AUTOSAR XML (schema 4-0-3)
standard types defined: Boolean, UInt16
package /AUTOSAR_Platform/DataConstrs
  range DC_Boolean: raw 0..1
  range DC_UInt16: raw 0..65535
package /PATAC/Facility/DataTypes/Implementation
  compu method COMPU_Boolean: 0=FALSE, 1=TRUE
  unit NoUnit: factor-si-to-unit=1, offset-si-to-unit=0
package /PATAC/MSM/ComponentTypes
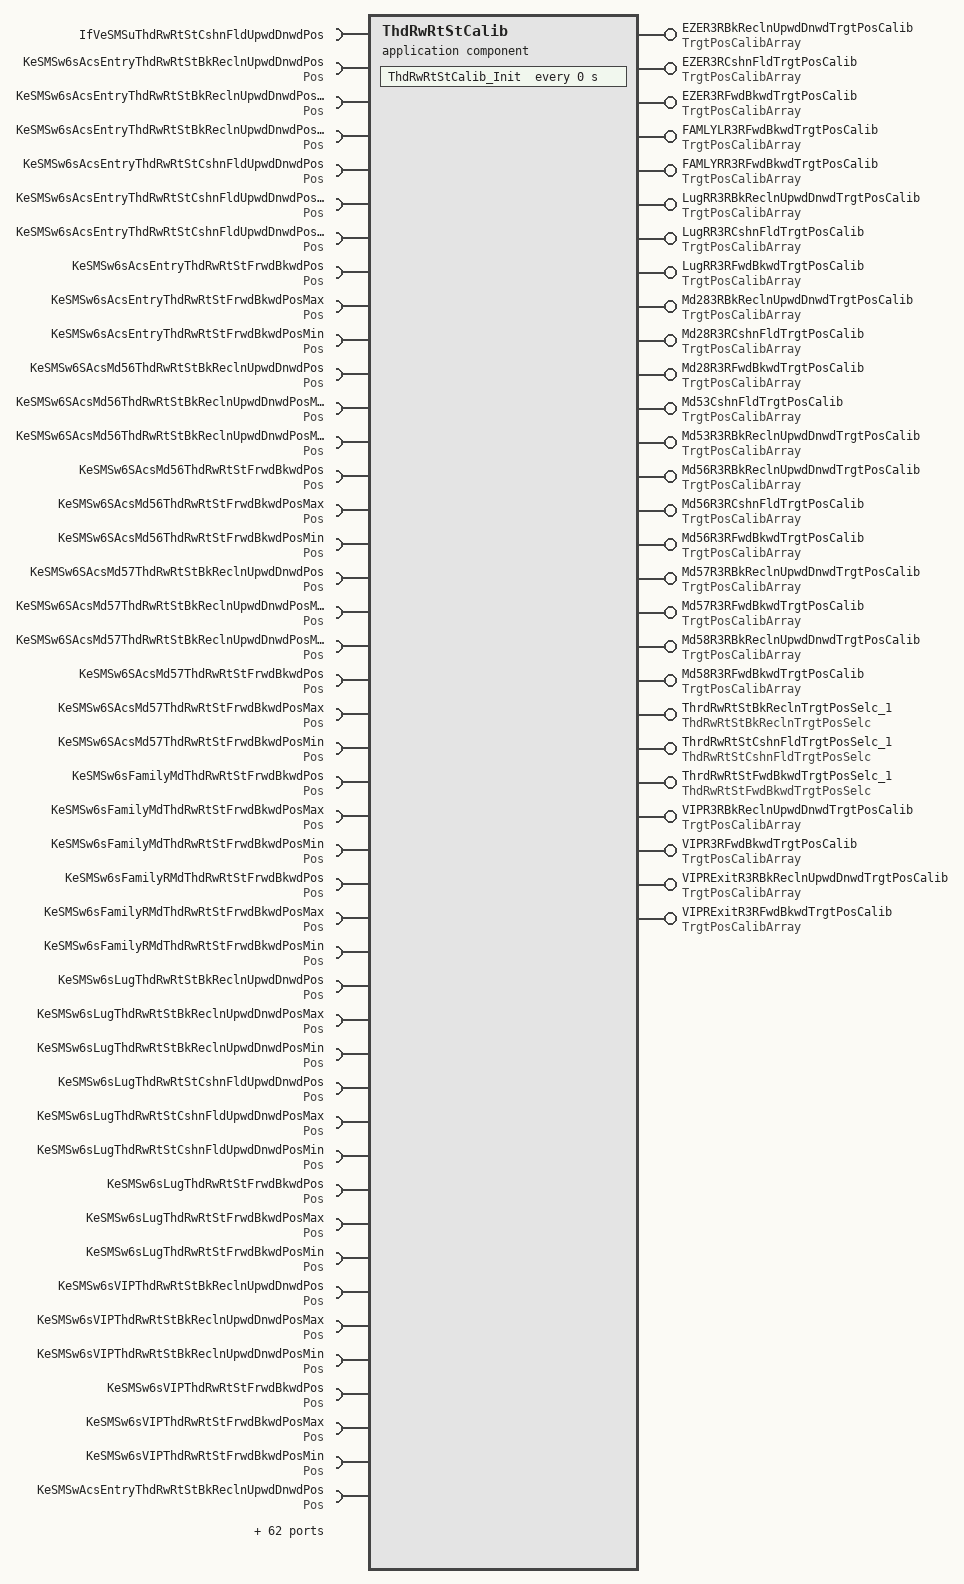
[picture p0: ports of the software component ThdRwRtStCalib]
  application sw component type ThdRwRtStCalib
    27 x provide port:
      EZER3RBkReclnUpwdDnwdTrgtPosCalib: nonqueued-sender-com-spec{data-element=TrgtPosArray, init-value=[4095, 4095, 4095]}, provided-interface=TrgtPosCalibArray
      EZER3RCshnFldTrgtPosCalib: nonqueued-sender-com-spec{data-element=TrgtPosArray, init-value=[4095, 4095, 4095]}, provided-interface=TrgtPosCalibArray
      EZER3RFwdBkwdTrgtPosCalib: nonqueued-sender-com-spec{data-element=TrgtPosArray, init-value=[4095, 4095, 4095]}, provided-interface=TrgtPosCalibArray
      FAMLYLR3RFwdBkwdTrgtPosCalib: nonqueued-sender-com-spec{data-element=TrgtPosArray, init-value=[4095, 4095, 4095]}, provided-interface=TrgtPosCalibArray
      FAMLYRR3RFwdBkwdTrgtPosCalib: nonqueued-sender-com-spec{data-element=TrgtPosArray, init-value=[4095, 4095, 4095]}, provided-interface=TrgtPosCalibArray
      LugRR3RBkReclnUpwdDnwdTrgtPosCalib: nonqueued-sender-com-spec{data-element=TrgtPosArray, init-value=[4095, 4095, 4095]}, provided-interface=TrgtPosCalibArray
      LugRR3RCshnFldTrgtPosCalib: nonqueued-sender-com-spec{data-element=TrgtPosArray, init-value=[4095, 4095, 4095]}, provided-interface=TrgtPosCalibArray
      LugRR3RFwdBkwdTrgtPosCalib: nonqueued-sender-com-spec{data-element=TrgtPosArray, init-value=[4095, 4095, 4095]}, provided-interface=TrgtPosCalibArray
      Md283RBkReclnUpwdDnwdTrgtPosCalib: nonqueued-sender-com-spec{data-element=TrgtPosArray, init-value=[4095, 4095, 4095]}, provided-interface=TrgtPosCalibArray
      Md28R3RCshnFldTrgtPosCalib: nonqueued-sender-com-spec{data-element=TrgtPosArray, init-value=[4095, 4095, 4095]}, provided-interface=TrgtPosCalibArray
      Md28R3RFwdBkwdTrgtPosCalib: nonqueued-sender-com-spec{data-element=TrgtPosArray, init-value=[4095, 4095, 4095]}, provided-interface=TrgtPosCalibArray
      Md53CshnFldTrgtPosCalib: nonqueued-sender-com-spec{data-element=TrgtPosArray, init-value=[4095, 4095, 4095]}, provided-interface=TrgtPosCalibArray
      Md53R3RBkReclnUpwdDnwdTrgtPosCalib: nonqueued-sender-com-spec{data-element=TrgtPosArray, init-value=[4095, 4095, 4095]}, provided-interface=TrgtPosCalibArray
      Md56R3RBkReclnUpwdDnwdTrgtPosCalib: nonqueued-sender-com-spec{data-element=TrgtPosArray, init-value=[4095, 4095, 4095]}, provided-interface=TrgtPosCalibArray
      Md56R3RCshnFldTrgtPosCalib: nonqueued-sender-com-spec{data-element=TrgtPosArray, init-value=[4095, 4095, 4095]}, provided-interface=TrgtPosCalibArray
      Md56R3RFwdBkwdTrgtPosCalib: nonqueued-sender-com-spec{data-element=TrgtPosArray, init-value=[4095, 4095, 4095]}, provided-interface=TrgtPosCalibArray
      Md57R3RBkReclnUpwdDnwdTrgtPosCalib: nonqueued-sender-com-spec{data-element=TrgtPosArray, init-value=[4095, 4095, 4095]}, provided-interface=TrgtPosCalibArray
      Md57R3RFwdBkwdTrgtPosCalib: nonqueued-sender-com-spec{data-element=TrgtPosArray, init-value=[4095, 4095, 4095]}, provided-interface=TrgtPosCalibArray
      Md58R3RBkReclnUpwdDnwdTrgtPosCalib: nonqueued-sender-com-spec{data-element=TrgtPosArray, init-value=[4095, 4095, 4095]}, provided-interface=TrgtPosCalibArray
      Md58R3RFwdBkwdTrgtPosCalib: nonqueued-sender-com-spec{data-element=TrgtPosArray, init-value=[4095, 4095, 4095]}, provided-interface=TrgtPosCalibArray
      ThrdRwRtStBkReclnTrgtPosSelc_1: server-com-spec{operation=ThdRwRtStBkReclnTrgtPosSelc/Cal, queue-length=1}, provided-interface=ThdRwRtStBkReclnTrgtPosSelc
      ThrdRwRtStCshnFldTrgtPosSelc_1: server-com-spec{operation=ThdRwRtStCshnFldTrgtPosSelc/Cal, queue-length=1}, provided-interface=ThdRwRtStCshnFldTrgtPosSelc
      ThrdRwRtStFwdBkwdTrgtPosSelc_1: server-com-spec{operation=ThdRwRtStFwdBkwdTrgtPosSelc/Cal, queue-length=1}, provided-interface=ThdRwRtStFwdBkwdTrgtPosSelc
      VIPR3RBkReclnUpwdDnwdTrgtPosCalib: nonqueued-sender-com-spec{data-element=TrgtPosArray, init-value=[4095, 4095, 4095]}, provided-interface=TrgtPosCalibArray
      VIPR3RFwdBkwdTrgtPosCalib: nonqueued-sender-com-spec{data-element=TrgtPosArray, init-value=[4095, 4095, 4095]}, provided-interface=TrgtPosCalibArray
      VIPRExitR3RBkReclnUpwdDnwdTrgtPosCalib: nonqueued-sender-com-spec{data-element=TrgtPosArray, init-value=[4095, 4095, 4095]}, provided-interface=TrgtPosCalibArray
      VIPRExitR3RFwdBkwdTrgtPosCalib: nonqueued-sender-com-spec{data-element=TrgtPosArray, init-value=[4095, 4095, 4095]}, provided-interface=TrgtPosCalibArray
    106 x require port:
      IfVeSMSuThdRwRtStCshnFldUpwdDnwdPos: nonqueued-receiver-com-spec{data-element=Val, filter=data-filter-type=ALWAYS, init-value=0}, required-interface=IfVeSMSuThdRwRtStCshnFldUpwdDnwdPos
      KeSMSw6sAcsEntryThdRwRtStBkReclnUpwdDnwdPos: parameter-require-com-spec{init-value=2080, parameter=Val}, required-interface=Pos
      KeSMSw6sAcsEntryThdRwRtStBkReclnUpwdDnwdPosMax: parameter-require-com-spec{init-value=2095, parameter=Val}, required-interface=Pos
      KeSMSw6sAcsEntryThdRwRtStBkReclnUpwdDnwdPosMin: parameter-require-com-spec{init-value=2080, parameter=Val}, required-interface=Pos
      KeSMSw6sAcsEntryThdRwRtStCshnFldUpwdDnwdPos: parameter-require-com-spec{init-value=0, parameter=Val}, required-interface=Pos
      KeSMSw6sAcsEntryThdRwRtStCshnFldUpwdDnwdPosMax: parameter-require-com-spec{init-value=0, parameter=Val}, required-interface=Pos
      KeSMSw6sAcsEntryThdRwRtStCshnFldUpwdDnwdPosMin: parameter-require-com-spec{init-value=0, parameter=Val}, required-interface=Pos
      KeSMSw6sAcsEntryThdRwRtStFrwdBkwdPos: parameter-require-com-spec{init-value=2760, parameter=Val}, required-interface=Pos
      KeSMSw6sAcsEntryThdRwRtStFrwdBkwdPosMax: parameter-require-com-spec{init-value=4000, parameter=Val}, required-interface=Pos
      KeSMSw6sAcsEntryThdRwRtStFrwdBkwdPosMin: parameter-require-com-spec{init-value=2760, parameter=Val}, required-interface=Pos
      KeSMSw6SAcsMd56ThdRwRtStBkReclnUpwdDnwdPos: parameter-require-com-spec{init-value=2080, parameter=Val}, required-interface=Pos
      KeSMSw6SAcsMd56ThdRwRtStBkReclnUpwdDnwdPosMax: parameter-require-com-spec{init-value=2080, parameter=Val}, required-interface=Pos
      KeSMSw6SAcsMd56ThdRwRtStBkReclnUpwdDnwdPosMin: parameter-require-com-spec{init-value=2080, parameter=Val}, required-interface=Pos
      KeSMSw6SAcsMd56ThdRwRtStFrwdBkwdPos: parameter-require-com-spec{init-value=2080, parameter=Val}, required-interface=Pos
      KeSMSw6SAcsMd56ThdRwRtStFrwdBkwdPosMax: parameter-require-com-spec{init-value=2080, parameter=Val}, required-interface=Pos
      KeSMSw6SAcsMd56ThdRwRtStFrwdBkwdPosMin: parameter-require-com-spec{init-value=2080, parameter=Val}, required-interface=Pos
      KeSMSw6SAcsMd57ThdRwRtStBkReclnUpwdDnwdPos: parameter-require-com-spec{init-value=2080, parameter=Val}, required-interface=Pos
      KeSMSw6SAcsMd57ThdRwRtStBkReclnUpwdDnwdPosMax: parameter-require-com-spec{init-value=2080, parameter=Val}, required-interface=Pos
      KeSMSw6SAcsMd57ThdRwRtStBkReclnUpwdDnwdPosMin: parameter-require-com-spec{init-value=2080, parameter=Val}, required-interface=Pos
      KeSMSw6SAcsMd57ThdRwRtStFrwdBkwdPos: parameter-require-com-spec{init-value=2080, parameter=Val}, required-interface=Pos
      KeSMSw6SAcsMd57ThdRwRtStFrwdBkwdPosMax: parameter-require-com-spec{init-value=2080, parameter=Val}, required-interface=Pos
      KeSMSw6SAcsMd57ThdRwRtStFrwdBkwdPosMin: parameter-require-com-spec{init-value=2080, parameter=Val}, required-interface=Pos
      KeSMSw6sFamilyMdThdRwRtStFrwdBkwdPos: parameter-require-com-spec{init-value=0, parameter=Val}, required-interface=Pos
      KeSMSw6sFamilyMdThdRwRtStFrwdBkwdPosMax: parameter-require-com-spec{init-value=0, parameter=Val}, required-interface=Pos
      KeSMSw6sFamilyMdThdRwRtStFrwdBkwdPosMin: parameter-require-com-spec{init-value=0, parameter=Val}, required-interface=Pos
      KeSMSw6sFamilyRMdThdRwRtStFrwdBkwdPos: parameter-require-com-spec{init-value=0, parameter=Val}, required-interface=Pos
      KeSMSw6sFamilyRMdThdRwRtStFrwdBkwdPosMax: parameter-require-com-spec{init-value=0, parameter=Val}, required-interface=Pos
      KeSMSw6sFamilyRMdThdRwRtStFrwdBkwdPosMin: parameter-require-com-spec{init-value=0, parameter=Val}, required-interface=Pos
      KeSMSw6sLugThdRwRtStBkReclnUpwdDnwdPos: parameter-require-com-spec{init-value=0, parameter=Val}, required-interface=Pos
      KeSMSw6sLugThdRwRtStBkReclnUpwdDnwdPosMax: parameter-require-com-spec{init-value=0, parameter=Val}, required-interface=Pos
      KeSMSw6sLugThdRwRtStBkReclnUpwdDnwdPosMin: parameter-require-com-spec{init-value=0, parameter=Val}, required-interface=Pos
      KeSMSw6sLugThdRwRtStCshnFldUpwdDnwdPos: parameter-require-com-spec{init-value=4000, parameter=Val}, required-interface=Pos
      KeSMSw6sLugThdRwRtStCshnFldUpwdDnwdPosMax: parameter-require-com-spec{init-value=4000, parameter=Val}, required-interface=Pos
      KeSMSw6sLugThdRwRtStCshnFldUpwdDnwdPosMin: parameter-require-com-spec{init-value=4000, parameter=Val}, required-interface=Pos
      KeSMSw6sLugThdRwRtStFrwdBkwdPos: parameter-require-com-spec{init-value=0, parameter=Val}, required-interface=Pos
      KeSMSw6sLugThdRwRtStFrwdBkwdPosMax: parameter-require-com-spec{init-value=0, parameter=Val}, required-interface=Pos
      KeSMSw6sLugThdRwRtStFrwdBkwdPosMin: parameter-require-com-spec{init-value=0, parameter=Val}, required-interface=Pos
      KeSMSw6sVIPThdRwRtStBkReclnUpwdDnwdPos: parameter-require-com-spec{init-value=0, parameter=Val}, required-interface=Pos
      KeSMSw6sVIPThdRwRtStBkReclnUpwdDnwdPosMax: parameter-require-com-spec{init-value=0, parameter=Val}, required-interface=Pos
      KeSMSw6sVIPThdRwRtStBkReclnUpwdDnwdPosMin: parameter-require-com-spec{init-value=0, parameter=Val}, required-interface=Pos
      KeSMSw6sVIPThdRwRtStFrwdBkwdPos: parameter-require-com-spec{init-value=4000, parameter=Val}, required-interface=Pos
      KeSMSw6sVIPThdRwRtStFrwdBkwdPosMax: parameter-require-com-spec{init-value=4000, parameter=Val}, required-interface=Pos
      KeSMSw6sVIPThdRwRtStFrwdBkwdPosMin: parameter-require-com-spec{init-value=4000, parameter=Val}, required-interface=Pos
      KeSMSwAcsEntryThdRwRtStBkReclnUpwdDnwdPos: parameter-require-com-spec{init-value=2080, parameter=Val}, required-interface=Pos
      KeSMSwAcsEntryThdRwRtStBkReclnUpwdDnwdPosMax: parameter-require-com-spec{init-value=2095, parameter=Val}, required-interface=Pos
      KeSMSwAcsEntryThdRwRtStBkReclnUpwdDnwdPosMin: parameter-require-com-spec{init-value=2080, parameter=Val}, required-interface=Pos
      KeSMSwAcsEntryThdRwRtStCshnFldUpwdDnwdPos: parameter-require-com-spec{init-value=0, parameter=Val}, required-interface=Pos
      KeSMSwAcsEntryThdRwRtStCshnFldUpwdDnwdPosMax: parameter-require-com-spec{init-value=0, parameter=Val}, required-interface=Pos
      KeSMSwAcsEntryThdRwRtStCshnFldUpwdDnwdPosMin: parameter-require-com-spec{init-value=0, parameter=Val}, required-interface=Pos
      KeSMSwAcsEntryThdRwRtStFrwdBkwdPos: parameter-require-com-spec{init-value=2760, parameter=Val}, required-interface=Pos
      KeSMSwAcsEntryThdRwRtStFrwdBkwdPosMax: parameter-require-com-spec{init-value=4000, parameter=Val}, required-interface=Pos
      KeSMSwAcsEntryThdRwRtStFrwdBkwdPosMin: parameter-require-com-spec{init-value=2760, parameter=Val}, required-interface=Pos
      KeSMSwAcsMd53ThdRwRtBkReclnUpwdDnwdPos: parameter-require-com-spec{init-value=2080, parameter=Val}, required-interface=Pos
      KeSMSwAcsMd53ThdRwRtBkReclnUpwdDnwdPosMax: parameter-require-com-spec{init-value=2080, parameter=Val}, required-interface=Pos
      KeSMSwAcsMd53ThdRwRtBkReclnUpwdDnwdPosMin: parameter-require-com-spec{init-value=2080, parameter=Val}, required-interface=Pos
      KeSMSwAcsMd53ThdRwRtFldUpwdDnwdPos: parameter-require-com-spec{init-value=0, parameter=Val}, required-interface=Pos
      KeSMSwAcsMd53ThdRwRtFldUpwdDnwdPosMax: parameter-require-com-spec{init-value=0, parameter=Val}, required-interface=Pos
      KeSMSwAcsMd53ThdRwRtFldUpwdDnwdPosMin: parameter-require-com-spec{init-value=0, parameter=Val}, required-interface=Pos
      KeSMSwAcsMd56ThdRwRtStBkReclnUpwdDnwdPos: parameter-require-com-spec{init-value=2080, parameter=Val}, required-interface=Pos
      KeSMSwAcsMd56ThdRwRtStBkReclnUpwdDnwdPosMax: parameter-require-com-spec{init-value=2080, parameter=Val}, required-interface=Pos
      KeSMSwAcsMd56ThdRwRtStBkReclnUpwdDnwdPosMin: parameter-require-com-spec{init-value=2080, parameter=Val}, required-interface=Pos
      KeSMSwAcsMd56ThdRwRtStCshnFldUpwdDnwdPos: parameter-require-com-spec{init-value=2080, parameter=Val}, required-interface=Pos
      KeSMSwAcsMd56ThdRwRtStCshnFldUpwdDnwdPosMax: parameter-require-com-spec{init-value=2080, parameter=Val}, required-interface=Pos
      KeSMSwAcsMd56ThdRwRtStCshnFldUpwdDnwdPosMin: parameter-require-com-spec{init-value=2080, parameter=Val}, required-interface=Pos
      KeSMSwAcsMd56ThdRwRtStFrwdBkwdPos: parameter-require-com-spec{init-value=2080, parameter=Val}, required-interface=Pos
      KeSMSwAcsMd56ThdRwRtStFrwdBkwdPosMax: parameter-require-com-spec{init-value=2080, parameter=Val}, required-interface=Pos
      KeSMSwAcsMd56ThdRwRtStFrwdBkwdPosMin: parameter-require-com-spec{init-value=2080, parameter=Val}, required-interface=Pos
      KeSMSwAcsMd57ThdRwRtStBkReclnUpwdDnwdPos: parameter-require-com-spec{init-value=2080, parameter=Val}, required-interface=Pos
      KeSMSwAcsMd57ThdRwRtStBkReclnUpwdDnwdPosMax: parameter-require-com-spec{init-value=2080, parameter=Val}, required-interface=Pos
      KeSMSwAcsMd57ThdRwRtStBkReclnUpwdDnwdPosMin: parameter-require-com-spec{init-value=2080, parameter=Val}, required-interface=Pos
      KeSMSwAcsMd57ThdRwRtStFrwdBkwdPos: parameter-require-com-spec{init-value=2080, parameter=Val}, required-interface=Pos
      KeSMSwAcsMd57ThdRwRtStFrwdBkwdPosMax: parameter-require-com-spec{init-value=2080, parameter=Val}, required-interface=Pos
      KeSMSwAcsMd57ThdRwRtStFrwdBkwdPosMin: parameter-require-com-spec{init-value=2080, parameter=Val}, required-interface=Pos
      KeSMSwAcsMd7ThdRwRtStBkReclnUpwdDnwdPos: parameter-require-com-spec{init-value=0, parameter=Val}, required-interface=Pos
      KeSMSwAcsMd7ThdRwRtStBkReclnUpwdDnwdPosMax: parameter-require-com-spec{init-value=0, parameter=Val}, required-interface=Pos
      KeSMSwAcsMd7ThdRwRtStBkReclnUpwdDnwdPosMin: parameter-require-com-spec{init-value=0, parameter=Val}, required-interface=Pos
      KeSMSwAcsMd7ThdRwRtStCshnFldUpwdDnwdPos: parameter-require-com-spec{init-value=0, parameter=Val}, required-interface=Pos
      KeSMSwAcsMd7ThdRwRtStCshnFldUpwdDnwdPosMax: parameter-require-com-spec{init-value=0, parameter=Val}, required-interface=Pos
      KeSMSwAcsMd7ThdRwRtStCshnFldUpwdDnwdPosMin: parameter-require-com-spec{init-value=0, parameter=Val}, required-interface=Pos
      KeSMSwAcsMd7ThdRwRtStFrwdBkwdPos: parameter-require-com-spec{init-value=0, parameter=Val}, required-interface=Pos
      KeSMSwAcsMd7ThdRwRtStFrwdBkwdPosMax: parameter-require-com-spec{init-value=0, parameter=Val}, required-interface=Pos
      KeSMSwAcsMd7ThdRwRtStFrwdBkwdPosMin: parameter-require-com-spec{init-value=0, parameter=Val}, required-interface=Pos
      KeSMSwFamilyMdThdRwRtStFrwdBkwdPos: parameter-require-com-spec{init-value=0, parameter=Val}, required-interface=Pos
      KeSMSwFamilyMdThdRwRtStFrwdBkwdPosMax: parameter-require-com-spec{init-value=0, parameter=Val}, required-interface=Pos
      KeSMSwFamilyMdThdRwRtStFrwdBkwdPosMin: parameter-require-com-spec{init-value=0, parameter=Val}, required-interface=Pos
      KeSMSwFamilyRMdThdRwRtStFrwdBkwdPos: parameter-require-com-spec{init-value=0, parameter=Val}, required-interface=Pos
      KeSMSwFamilyRMdThdRwRtStFrwdBkwdPosMax: parameter-require-com-spec{init-value=0, parameter=Val}, required-interface=Pos
      KeSMSwFamilyRMdThdRwRtStFrwdBkwdPosMin: parameter-require-com-spec{init-value=0, parameter=Val}, required-interface=Pos
      KeSMSwLugThdRwRtStBkReclnUpwdDnwdPos: parameter-require-com-spec{init-value=0, parameter=Val}, required-interface=Pos
      KeSMSwLugThdRwRtStBkReclnUpwdDnwdPosMax: parameter-require-com-spec{init-value=0, parameter=Val}, required-interface=Pos
      KeSMSwLugThdRwRtStBkReclnUpwdDnwdPosMin: parameter-require-com-spec{init-value=0, parameter=Val}, required-interface=Pos
      KeSMSwLugThdRwRtStCshnFldUpwdDnwdPos: parameter-require-com-spec{init-value=4000, parameter=Val}, required-interface=Pos
      KeSMSwLugThdRwRtStCshnFldUpwdDnwdPosMax: parameter-require-com-spec{init-value=4000, parameter=Val}, required-interface=Pos
      KeSMSwLugThdRwRtStCshnFldUpwdDnwdPosMin: parameter-require-com-spec{init-value=4000, parameter=Val}, required-interface=Pos
      KeSMSwLugThdRwRtStFrwdBkwdPos: parameter-require-com-spec{init-value=4000, parameter=Val}, required-interface=Pos
      KeSMSwLugThdRwRtStFrwdBkwdPosMax: parameter-require-com-spec{init-value=4000, parameter=Val}, required-interface=Pos
      KeSMSwLugThdRwRtStFrwdBkwdPosMin: parameter-require-com-spec{init-value=4000, parameter=Val}, required-interface=Pos
      KeSMSwVIPThdRwRtStBkReclnUpwdDnwdPos: parameter-require-com-spec{init-value=0, parameter=Val}, required-interface=Pos
      KeSMSwVIPThdRwRtStBkReclnUpwdDnwdPosMax: parameter-require-com-spec{init-value=0, parameter=Val}, required-interface=Pos
      KeSMSwVIPThdRwRtStBkReclnUpwdDnwdPosMin: parameter-require-com-spec{init-value=0, parameter=Val}, required-interface=Pos
      KeSMSwVIPThdRwRtStFrwdBkwdPos: parameter-require-com-spec{init-value=4000, parameter=Val}, required-interface=Pos
      KeSMSwVIPThdRwRtStFrwdBkwdPosMax: parameter-require-com-spec{init-value=4000, parameter=Val}, required-interface=Pos
      KeSMSwVIPThdRwRtStFrwdBkwdPosMin: parameter-require-com-spec{init-value=4000, parameter=Val}, required-interface=Pos
      Md58TrgtPos: required-com-specs=[Md58TrgtPos/Get, Md58TrgtPos/Set], required-interface=Md58TrgtPos
      StNumFlg: required-interface=StNumFlg
        required-com-specs:
          data-element=Is4s, filter=data-filter-type=ALWAYS, init-value=0
          data-element=Is6s, filter=data-filter-type=ALWAYS, init-value=0
          data-element=Is6s7s, filter=data-filter-type=ALWAYS, init-value=0
          data-element=Is7s, filter=data-filter-type=ALWAYS, init-value=0
      VIPRExit557TrgtPos: required-com-specs=[VIPRExit557TrgtPos/Get, VIPRExit557TrgtPos/Set], required-interface=VIPRExit557TrgtPos
    behavior ThdRwRtStCalib_InternalBehavior
      timing event ThdRwRtStCalib_InitEvent: start-on-event=ThdRwRtStCalib_Init, period=0
      operation invoked event OIT_ThrdRwRtStBkReclnTrgtPosSelc_1_Cal_ThrdRwRtStBkReclnTrgtPosSelc_1_Cal: start-on-event=ThrdRwRtStBkReclnTrgtPosSelc_1_Cal, operation=ThrdRwRtStBkReclnTrgtPosSelc_1.Cal
      operation invoked event OIT_ThrdRwRtStCshnFldTrgtPosSelc_1_Cal_ThrdRwRtStCshnFldTrgtPosSelc_1_Cal: start-on-event=ThrdRwRtStCshnFldTrgtPosSelc_1_Cal, operation=ThrdRwRtStCshnFldTrgtPosSelc_1.Cal
      operation invoked event OIT_ThrdRwRtStFwdBkwdTrgtPosSelc_1_Cal_ThrdRwRtStFwdBkwdTrgtPosSelc_1_Cal: start-on-event=ThrdRwRtStFwdBkwdTrgtPosSelc_1_Cal, operation=ThrdRwRtStFwdBkwdTrgtPosSelc_1.Cal
      4 x runnable:
        ThdRwRtStCalib_Init
          102 x parameter access:
            PA_KeSMSw6sAcsEntryThdRwRtStBkReclnUpwdDnwdPos_Val: accessed-parameter=KeSMSw6sAcsEntryThdRwRtStBkReclnUpwdDnwdPos.Val
            PA_KeSMSw6sAcsEntryThdRwRtStBkReclnUpwdDnwdPosMax_Val: accessed-parameter=KeSMSw6sAcsEntryThdRwRtStBkReclnUpwdDnwdPosMax.Val
            PA_KeSMSw6sAcsEntryThdRwRtStBkReclnUpwdDnwdPosMin_Val: accessed-parameter=KeSMSw6sAcsEntryThdRwRtStBkReclnUpwdDnwdPosMin.Val
            PA_KeSMSw6sAcsEntryThdRwRtStCshnFldUpwdDnwdPos_Val: accessed-parameter=KeSMSw6sAcsEntryThdRwRtStCshnFldUpwdDnwdPos.Val
            PA_KeSMSw6sAcsEntryThdRwRtStCshnFldUpwdDnwdPosMax_Val: accessed-parameter=KeSMSw6sAcsEntryThdRwRtStCshnFldUpwdDnwdPosMax.Val
            PA_KeSMSw6sAcsEntryThdRwRtStCshnFldUpwdDnwdPosMin_Val: accessed-parameter=KeSMSw6sAcsEntryThdRwRtStCshnFldUpwdDnwdPosMin.Val
            PA_KeSMSw6sAcsEntryThdRwRtStFrwdBkwdPos_Val: accessed-parameter=KeSMSw6sAcsEntryThdRwRtStFrwdBkwdPos.Val
            PA_KeSMSw6sAcsEntryThdRwRtStFrwdBkwdPosMax_Val: accessed-parameter=KeSMSw6sAcsEntryThdRwRtStFrwdBkwdPosMax.Val
            PA_KeSMSw6sAcsEntryThdRwRtStFrwdBkwdPosMin_Val: accessed-parameter=KeSMSw6sAcsEntryThdRwRtStFrwdBkwdPosMin.Val
            PA_KeSMSw6SAcsMd56ThdRwRtStBkReclnUpwdDnwdPos_Val: accessed-parameter=KeSMSw6SAcsMd56ThdRwRtStBkReclnUpwdDnwdPos.Val
            PA_KeSMSw6SAcsMd56ThdRwRtStBkReclnUpwdDnwdPosMax_Val: accessed-parameter=KeSMSw6SAcsMd56ThdRwRtStBkReclnUpwdDnwdPosMax.Val
            PA_KeSMSw6SAcsMd56ThdRwRtStBkReclnUpwdDnwdPosMin_Val: accessed-parameter=KeSMSw6SAcsMd56ThdRwRtStBkReclnUpwdDnwdPosMin.Val
            PA_KeSMSw6SAcsMd56ThdRwRtStFrwdBkwdPos_Val: accessed-parameter=KeSMSw6SAcsMd56ThdRwRtStFrwdBkwdPos.Val
            PA_KeSMSw6SAcsMd56ThdRwRtStFrwdBkwdPosMax_Val: accessed-parameter=KeSMSw6SAcsMd56ThdRwRtStFrwdBkwdPosMax.Val
            PA_KeSMSw6SAcsMd56ThdRwRtStFrwdBkwdPosMin_Val: accessed-parameter=KeSMSw6SAcsMd56ThdRwRtStFrwdBkwdPosMin.Val
            PA_KeSMSw6SAcsMd57ThdRwRtStBkReclnUpwdDnwdPos_Val: accessed-parameter=KeSMSw6SAcsMd57ThdRwRtStBkReclnUpwdDnwdPos.Val
            PA_KeSMSw6SAcsMd57ThdRwRtStBkReclnUpwdDnwdPosMax_Val: accessed-parameter=KeSMSw6SAcsMd57ThdRwRtStBkReclnUpwdDnwdPosMax.Val
            PA_KeSMSw6SAcsMd57ThdRwRtStBkReclnUpwdDnwdPosMin_Val: accessed-parameter=KeSMSw6SAcsMd57ThdRwRtStBkReclnUpwdDnwdPosMin.Val
            PA_KeSMSw6SAcsMd57ThdRwRtStFrwdBkwdPos_Val: accessed-parameter=KeSMSw6SAcsMd57ThdRwRtStFrwdBkwdPos.Val
            PA_KeSMSw6SAcsMd57ThdRwRtStFrwdBkwdPosMax_Val: accessed-parameter=KeSMSw6SAcsMd57ThdRwRtStFrwdBkwdPosMax.Val
            PA_KeSMSw6SAcsMd57ThdRwRtStFrwdBkwdPosMin_Val: accessed-parameter=KeSMSw6SAcsMd57ThdRwRtStFrwdBkwdPosMin.Val
            PA_KeSMSw6sFamilyMdThdRwRtStFrwdBkwdPos_Val: accessed-parameter=KeSMSw6sFamilyMdThdRwRtStFrwdBkwdPos.Val
            PA_KeSMSw6sFamilyMdThdRwRtStFrwdBkwdPosMax_Val: accessed-parameter=KeSMSw6sFamilyMdThdRwRtStFrwdBkwdPosMax.Val
            PA_KeSMSw6sFamilyMdThdRwRtStFrwdBkwdPosMin_Val: accessed-parameter=KeSMSw6sFamilyMdThdRwRtStFrwdBkwdPosMin.Val
            PA_KeSMSw6sFamilyRMdThdRwRtStFrwdBkwdPos_Val: accessed-parameter=KeSMSw6sFamilyRMdThdRwRtStFrwdBkwdPos.Val
            PA_KeSMSw6sFamilyRMdThdRwRtStFrwdBkwdPosMax_Val: accessed-parameter=KeSMSw6sFamilyRMdThdRwRtStFrwdBkwdPosMax.Val
            PA_KeSMSw6sFamilyRMdThdRwRtStFrwdBkwdPosMin_Val: accessed-parameter=KeSMSw6sFamilyRMdThdRwRtStFrwdBkwdPosMin.Val
            PA_KeSMSw6sLugThdRwRtStBkReclnUpwdDnwdPos_Val: accessed-parameter=KeSMSw6sLugThdRwRtStBkReclnUpwdDnwdPos.Val
            PA_KeSMSw6sLugThdRwRtStBkReclnUpwdDnwdPosMax_Val: accessed-parameter=KeSMSw6sLugThdRwRtStBkReclnUpwdDnwdPosMax.Val
            PA_KeSMSw6sLugThdRwRtStBkReclnUpwdDnwdPosMin_Val: accessed-parameter=KeSMSw6sLugThdRwRtStBkReclnUpwdDnwdPosMin.Val
            PA_KeSMSw6sLugThdRwRtStCshnFldUpwdDnwdPos_Val: accessed-parameter=KeSMSw6sLugThdRwRtStCshnFldUpwdDnwdPos.Val
            PA_KeSMSw6sLugThdRwRtStCshnFldUpwdDnwdPosMax_Val: accessed-parameter=KeSMSw6sLugThdRwRtStCshnFldUpwdDnwdPosMax.Val
            PA_KeSMSw6sLugThdRwRtStCshnFldUpwdDnwdPosMin_Val: accessed-parameter=KeSMSw6sLugThdRwRtStCshnFldUpwdDnwdPosMin.Val
            PA_KeSMSw6sLugThdRwRtStFrwdBkwdPos_Val: accessed-parameter=KeSMSw6sLugThdRwRtStFrwdBkwdPos.Val
            PA_KeSMSw6sLugThdRwRtStFrwdBkwdPosMax_Val: accessed-parameter=KeSMSw6sLugThdRwRtStFrwdBkwdPosMax.Val
            PA_KeSMSw6sLugThdRwRtStFrwdBkwdPosMin_Val: accessed-parameter=KeSMSw6sLugThdRwRtStFrwdBkwdPosMin.Val
            PA_KeSMSw6sVIPThdRwRtStBkReclnUpwdDnwdPos_Val: accessed-parameter=KeSMSw6sVIPThdRwRtStBkReclnUpwdDnwdPos.Val
            PA_KeSMSw6sVIPThdRwRtStBkReclnUpwdDnwdPosMax_Val: accessed-parameter=KeSMSw6sVIPThdRwRtStBkReclnUpwdDnwdPosMax.Val
            PA_KeSMSw6sVIPThdRwRtStBkReclnUpwdDnwdPosMin_Val: accessed-parameter=KeSMSw6sVIPThdRwRtStBkReclnUpwdDnwdPosMin.Val
            PA_KeSMSw6sVIPThdRwRtStFrwdBkwdPos_Val: accessed-parameter=KeSMSw6sVIPThdRwRtStFrwdBkwdPos.Val
            PA_KeSMSw6sVIPThdRwRtStFrwdBkwdPosMax_Val: accessed-parameter=KeSMSw6sVIPThdRwRtStFrwdBkwdPosMax.Val
            PA_KeSMSw6sVIPThdRwRtStFrwdBkwdPosMin_Val: accessed-parameter=KeSMSw6sVIPThdRwRtStFrwdBkwdPosMin.Val
            PA_KeSMSwAcsEntryThdRwRtStBkReclnUpwdDnwdPos_Val: accessed-parameter=KeSMSwAcsEntryThdRwRtStBkReclnUpwdDnwdPos.Val
            PA_KeSMSwAcsEntryThdRwRtStBkReclnUpwdDnwdPosMax_Val: accessed-parameter=KeSMSwAcsEntryThdRwRtStBkReclnUpwdDnwdPosMax.Val
            PA_KeSMSwAcsEntryThdRwRtStBkReclnUpwdDnwdPosMin_Val: accessed-parameter=KeSMSwAcsEntryThdRwRtStBkReclnUpwdDnwdPosMin.Val
            PA_KeSMSwAcsEntryThdRwRtStCshnFldUpwdDnwdPos_Val: accessed-parameter=KeSMSwAcsEntryThdRwRtStCshnFldUpwdDnwdPos.Val
            PA_KeSMSwAcsEntryThdRwRtStCshnFldUpwdDnwdPosMax_Val: accessed-parameter=KeSMSwAcsEntryThdRwRtStCshnFldUpwdDnwdPosMax.Val
            PA_KeSMSwAcsEntryThdRwRtStCshnFldUpwdDnwdPosMin_Val: accessed-parameter=KeSMSwAcsEntryThdRwRtStCshnFldUpwdDnwdPosMin.Val
            PA_KeSMSwAcsEntryThdRwRtStFrwdBkwdPos_Val: accessed-parameter=KeSMSwAcsEntryThdRwRtStFrwdBkwdPos.Val
            PA_KeSMSwAcsEntryThdRwRtStFrwdBkwdPosMax_Val: accessed-parameter=KeSMSwAcsEntryThdRwRtStFrwdBkwdPosMax.Val
            PA_KeSMSwAcsEntryThdRwRtStFrwdBkwdPosMin_Val: accessed-parameter=KeSMSwAcsEntryThdRwRtStFrwdBkwdPosMin.Val
            PA_KeSMSwAcsMd53ThdRwRtBkReclnUpwdDnwdPos_Val: accessed-parameter=KeSMSwAcsMd53ThdRwRtBkReclnUpwdDnwdPos.Val
            PA_KeSMSwAcsMd53ThdRwRtBkReclnUpwdDnwdPosMax_Val: accessed-parameter=KeSMSwAcsMd53ThdRwRtBkReclnUpwdDnwdPosMax.Val
            PA_KeSMSwAcsMd53ThdRwRtBkReclnUpwdDnwdPosMin_Val: accessed-parameter=KeSMSwAcsMd53ThdRwRtBkReclnUpwdDnwdPosMin.Val
            PA_KeSMSwAcsMd53ThdRwRtFldUpwdDnwdPos_Val: accessed-parameter=KeSMSwAcsMd53ThdRwRtFldUpwdDnwdPos.Val
            PA_KeSMSwAcsMd53ThdRwRtFldUpwdDnwdPosMax_Val: accessed-parameter=KeSMSwAcsMd53ThdRwRtFldUpwdDnwdPosMax.Val
            PA_KeSMSwAcsMd53ThdRwRtFldUpwdDnwdPosMin_Val: accessed-parameter=KeSMSwAcsMd53ThdRwRtFldUpwdDnwdPosMin.Val
            PA_KeSMSwAcsMd56ThdRwRtStBkReclnUpwdDnwdPos_Val: accessed-parameter=KeSMSwAcsMd56ThdRwRtStBkReclnUpwdDnwdPos.Val
            PA_KeSMSwAcsMd56ThdRwRtStBkReclnUpwdDnwdPosMax_Val: accessed-parameter=KeSMSwAcsMd56ThdRwRtStBkReclnUpwdDnwdPosMax.Val
            PA_KeSMSwAcsMd56ThdRwRtStBkReclnUpwdDnwdPosMin_Val: accessed-parameter=KeSMSwAcsMd56ThdRwRtStBkReclnUpwdDnwdPosMin.Val
            PA_KeSMSwAcsMd56ThdRwRtStCshnFldUpwdDnwdPos_Val: accessed-parameter=KeSMSwAcsMd56ThdRwRtStCshnFldUpwdDnwdPos.Val
            PA_KeSMSwAcsMd56ThdRwRtStCshnFldUpwdDnwdPosMax_Val: accessed-parameter=KeSMSwAcsMd56ThdRwRtStCshnFldUpwdDnwdPosMax.Val
            PA_KeSMSwAcsMd56ThdRwRtStCshnFldUpwdDnwdPosMin_Val: accessed-parameter=KeSMSwAcsMd56ThdRwRtStCshnFldUpwdDnwdPosMin.Val
            PA_KeSMSwAcsMd56ThdRwRtStFrwdBkwdPos_Val: accessed-parameter=KeSMSwAcsMd56ThdRwRtStFrwdBkwdPos.Val
            PA_KeSMSwAcsMd56ThdRwRtStFrwdBkwdPosMax_Val: accessed-parameter=KeSMSwAcsMd56ThdRwRtStFrwdBkwdPosMax.Val
            PA_KeSMSwAcsMd56ThdRwRtStFrwdBkwdPosMin_Val: accessed-parameter=KeSMSwAcsMd56ThdRwRtStFrwdBkwdPosMin.Val
            PA_KeSMSwAcsMd57ThdRwRtStBkReclnUpwdDnwdPos_Val: accessed-parameter=KeSMSwAcsMd57ThdRwRtStBkReclnUpwdDnwdPos.Val
            PA_KeSMSwAcsMd57ThdRwRtStBkReclnUpwdDnwdPosMax_Val: accessed-parameter=KeSMSwAcsMd57ThdRwRtStBkReclnUpwdDnwdPosMax.Val
            PA_KeSMSwAcsMd57ThdRwRtStBkReclnUpwdDnwdPosMin_Val: accessed-parameter=KeSMSwAcsMd57ThdRwRtStBkReclnUpwdDnwdPosMin.Val
            PA_KeSMSwAcsMd57ThdRwRtStFrwdBkwdPos_Val: accessed-parameter=KeSMSwAcsMd57ThdRwRtStFrwdBkwdPos.Val
            PA_KeSMSwAcsMd57ThdRwRtStFrwdBkwdPosMax_Val: accessed-parameter=KeSMSwAcsMd57ThdRwRtStFrwdBkwdPosMax.Val
            PA_KeSMSwAcsMd57ThdRwRtStFrwdBkwdPosMin_Val: accessed-parameter=KeSMSwAcsMd57ThdRwRtStFrwdBkwdPosMin.Val
            PA_KeSMSwAcsMd7ThdRwRtStBkReclnUpwdDnwdPos_Val: accessed-parameter=KeSMSwAcsMd7ThdRwRtStBkReclnUpwdDnwdPos.Val
            PA_KeSMSwAcsMd7ThdRwRtStBkReclnUpwdDnwdPosMax_Val: accessed-parameter=KeSMSwAcsMd7ThdRwRtStBkReclnUpwdDnwdPosMax.Val
            PA_KeSMSwAcsMd7ThdRwRtStBkReclnUpwdDnwdPosMin_Val: accessed-parameter=KeSMSwAcsMd7ThdRwRtStBkReclnUpwdDnwdPosMin.Val
            PA_KeSMSwAcsMd7ThdRwRtStCshnFldUpwdDnwdPos_Val: accessed-parameter=KeSMSwAcsMd7ThdRwRtStCshnFldUpwdDnwdPos.Val
            PA_KeSMSwAcsMd7ThdRwRtStCshnFldUpwdDnwdPosMax_Val: accessed-parameter=KeSMSwAcsMd7ThdRwRtStCshnFldUpwdDnwdPosMax.Val
            PA_KeSMSwAcsMd7ThdRwRtStCshnFldUpwdDnwdPosMin_Val: accessed-parameter=KeSMSwAcsMd7ThdRwRtStCshnFldUpwdDnwdPosMin.Val
            PA_KeSMSwAcsMd7ThdRwRtStFrwdBkwdPos_Val: accessed-parameter=KeSMSwAcsMd7ThdRwRtStFrwdBkwdPos.Val
            PA_KeSMSwAcsMd7ThdRwRtStFrwdBkwdPosMax_Val: accessed-parameter=KeSMSwAcsMd7ThdRwRtStFrwdBkwdPosMax.Val
            PA_KeSMSwAcsMd7ThdRwRtStFrwdBkwdPosMin_Val: accessed-parameter=KeSMSwAcsMd7ThdRwRtStFrwdBkwdPosMin.Val
            PA_KeSMSwFamilyMdThdRwRtStFrwdBkwdPos_Val: accessed-parameter=KeSMSwFamilyMdThdRwRtStFrwdBkwdPos.Val
            PA_KeSMSwFamilyMdThdRwRtStFrwdBkwdPosMax_Val: accessed-parameter=KeSMSwFamilyMdThdRwRtStFrwdBkwdPosMax.Val
            PA_KeSMSwFamilyMdThdRwRtStFrwdBkwdPosMin_Val: accessed-parameter=KeSMSwFamilyMdThdRwRtStFrwdBkwdPosMin.Val
            PA_KeSMSwFamilyRMdThdRwRtStFrwdBkwdPos_Val: accessed-parameter=KeSMSwFamilyRMdThdRwRtStFrwdBkwdPos.Val
            PA_KeSMSwFamilyRMdThdRwRtStFrwdBkwdPosMax_Val: accessed-parameter=KeSMSwFamilyRMdThdRwRtStFrwdBkwdPosMax.Val
            PA_KeSMSwFamilyRMdThdRwRtStFrwdBkwdPosMin_Val: accessed-parameter=KeSMSwFamilyRMdThdRwRtStFrwdBkwdPosMin.Val
            PA_KeSMSwLugThdRwRtStBkReclnUpwdDnwdPos_Val: accessed-parameter=KeSMSwLugThdRwRtStBkReclnUpwdDnwdPos.Val
            PA_KeSMSwLugThdRwRtStBkReclnUpwdDnwdPosMax_Val: accessed-parameter=KeSMSwLugThdRwRtStBkReclnUpwdDnwdPosMax.Val
            PA_KeSMSwLugThdRwRtStBkReclnUpwdDnwdPosMin_Val: accessed-parameter=KeSMSwLugThdRwRtStBkReclnUpwdDnwdPosMin.Val
            PA_KeSMSwLugThdRwRtStCshnFldUpwdDnwdPos_Val: accessed-parameter=KeSMSwLugThdRwRtStCshnFldUpwdDnwdPos.Val
            PA_KeSMSwLugThdRwRtStCshnFldUpwdDnwdPosMax_Val: accessed-parameter=KeSMSwLugThdRwRtStCshnFldUpwdDnwdPosMax.Val
            PA_KeSMSwLugThdRwRtStCshnFldUpwdDnwdPosMin_Val: accessed-parameter=KeSMSwLugThdRwRtStCshnFldUpwdDnwdPosMin.Val
            PA_KeSMSwLugThdRwRtStFrwdBkwdPos_Val: accessed-parameter=KeSMSwLugThdRwRtStFrwdBkwdPos.Val
            PA_KeSMSwLugThdRwRtStFrwdBkwdPosMax_Val: accessed-parameter=KeSMSwLugThdRwRtStFrwdBkwdPosMax.Val
            PA_KeSMSwLugThdRwRtStFrwdBkwdPosMin_Val: accessed-parameter=KeSMSwLugThdRwRtStFrwdBkwdPosMin.Val
            PA_KeSMSwVIPThdRwRtStBkReclnUpwdDnwdPos_Val: accessed-parameter=KeSMSwVIPThdRwRtStBkReclnUpwdDnwdPos.Val
            PA_KeSMSwVIPThdRwRtStBkReclnUpwdDnwdPosMax_Val: accessed-parameter=KeSMSwVIPThdRwRtStBkReclnUpwdDnwdPosMax.Val
            PA_KeSMSwVIPThdRwRtStBkReclnUpwdDnwdPosMin_Val: accessed-parameter=KeSMSwVIPThdRwRtStBkReclnUpwdDnwdPosMin.Val
            PA_KeSMSwVIPThdRwRtStFrwdBkwdPos_Val: accessed-parameter=KeSMSwVIPThdRwRtStFrwdBkwdPos.Val
            PA_KeSMSwVIPThdRwRtStFrwdBkwdPosMax_Val: accessed-parameter=KeSMSwVIPThdRwRtStFrwdBkwdPosMax.Val
            PA_KeSMSwVIPThdRwRtStFrwdBkwdPosMin_Val: accessed-parameter=KeSMSwVIPThdRwRtStFrwdBkwdPosMin.Val
        ThrdRwRtStBkReclnTrgtPosSelc_1_Cal
          data-receive-point-by-arguments:
            5 x access:
              REC_IfVeSMSuThdRwRtStCshnFldUpwdDnwdPos_Val: accessed-variable=IfVeSMSuThdRwRtStCshnFldUpwdDnwdPos.Val
              REC_StNumFlg_Is4s: accessed-variable=StNumFlg.Is4s
              REC_StNumFlg_Is6s: accessed-variable=StNumFlg.Is6s
              REC_StNumFlg_Is6s7s: accessed-variable=StNumFlg.Is6s7s
              REC_StNumFlg_Is7s: accessed-variable=StNumFlg.Is7s
          data-send-points:
            11 x access:
              SEND_EZER3RBkReclnUpwdDnwdTrgtPosCalib_TrgtPosArray: accessed-variable=EZER3RBkReclnUpwdDnwdTrgtPosCalib.TrgtPosArray
              SEND_LugRR3RBkReclnUpwdDnwdTrgtPosCalib_TrgtPosArray: accessed-variable=LugRR3RBkReclnUpwdDnwdTrgtPosCalib.TrgtPosArray
              SEND_Md283RBkReclnUpwdDnwdTrgtPosCalib_TrgtPosArray: accessed-variable=Md283RBkReclnUpwdDnwdTrgtPosCalib.TrgtPosArray
              SEND_Md53R3RBkReclnUpwdDnwdTrgtPosCalib_TrgtPosArray: accessed-variable=Md53R3RBkReclnUpwdDnwdTrgtPosCalib.TrgtPosArray
              SEND_Md{56..58}R3RBkReclnUpwdDnwdTrgtPosCalib_TrgtPosArray: accessed-variable=Md{56..58}R3RBkReclnUpwdDnwdTrgtPosCalib.TrgtPosArray
              SEND_Md58R3RFwdBkwdTrgtPosCalib_TrgtPosArray: accessed-variable=Md58R3RFwdBkwdTrgtPosCalib.TrgtPosArray
              SEND_VIPR3RBkReclnUpwdDnwdTrgtPosCalib_TrgtPosArray: accessed-variable=VIPR3RBkReclnUpwdDnwdTrgtPosCalib.TrgtPosArray
              SEND_VIPRExitR3RBkReclnUpwdDnwdTrgtPosCalib_TrgtPosArray: accessed-variable=VIPRExitR3RBkReclnUpwdDnwdTrgtPosCalib.TrgtPosArray
              SEND_VIPRExitR3RFwdBkwdTrgtPosCalib_TrgtPosArray: accessed-variable=VIPRExitR3RFwdBkwdTrgtPosCalib.TrgtPosArray
          102 x parameter access:
            PA_KeSMSw6sAcsEntryThdRwRtStBkReclnUpwdDnwdPos_Val: accessed-parameter=KeSMSw6sAcsEntryThdRwRtStBkReclnUpwdDnwdPos.Val
            PA_KeSMSw6sAcsEntryThdRwRtStBkReclnUpwdDnwdPosMax_Val: accessed-parameter=KeSMSw6sAcsEntryThdRwRtStBkReclnUpwdDnwdPosMax.Val
            PA_KeSMSw6sAcsEntryThdRwRtStBkReclnUpwdDnwdPosMin_Val: accessed-parameter=KeSMSw6sAcsEntryThdRwRtStBkReclnUpwdDnwdPosMin.Val
            PA_KeSMSw6sAcsEntryThdRwRtStCshnFldUpwdDnwdPos_Val: accessed-parameter=KeSMSw6sAcsEntryThdRwRtStCshnFldUpwdDnwdPos.Val
            PA_KeSMSw6sAcsEntryThdRwRtStCshnFldUpwdDnwdPosMax_Val: accessed-parameter=KeSMSw6sAcsEntryThdRwRtStCshnFldUpwdDnwdPosMax.Val
            PA_KeSMSw6sAcsEntryThdRwRtStCshnFldUpwdDnwdPosMin_Val: accessed-parameter=KeSMSw6sAcsEntryThdRwRtStCshnFldUpwdDnwdPosMin.Val
            PA_KeSMSw6sAcsEntryThdRwRtStFrwdBkwdPos_Val: accessed-parameter=KeSMSw6sAcsEntryThdRwRtStFrwdBkwdPos.Val
            PA_KeSMSw6sAcsEntryThdRwRtStFrwdBkwdPosMax_Val: accessed-parameter=KeSMSw6sAcsEntryThdRwRtStFrwdBkwdPosMax.Val
            PA_KeSMSw6sAcsEntryThdRwRtStFrwdBkwdPosMin_Val: accessed-parameter=KeSMSw6sAcsEntryThdRwRtStFrwdBkwdPosMin.Val
            PA_KeSMSw6SAcsMd56ThdRwRtStBkReclnUpwdDnwdPos_Val: accessed-parameter=KeSMSw6SAcsMd56ThdRwRtStBkReclnUpwdDnwdPos.Val
            PA_KeSMSw6SAcsMd56ThdRwRtStBkReclnUpwdDnwdPosMax_Val: accessed-parameter=KeSMSw6SAcsMd56ThdRwRtStBkReclnUpwdDnwdPosMax.Val
            PA_KeSMSw6SAcsMd56ThdRwRtStBkReclnUpwdDnwdPosMin_Val: accessed-parameter=KeSMSw6SAcsMd56ThdRwRtStBkReclnUpwdDnwdPosMin.Val
            PA_KeSMSw6SAcsMd56ThdRwRtStFrwdBkwdPos_Val: accessed-parameter=KeSMSw6SAcsMd56ThdRwRtStFrwdBkwdPos.Val
            PA_KeSMSw6SAcsMd56ThdRwRtStFrwdBkwdPosMax_Val: accessed-parameter=KeSMSw6SAcsMd56ThdRwRtStFrwdBkwdPosMax.Val
            PA_KeSMSw6SAcsMd56ThdRwRtStFrwdBkwdPosMin_Val: accessed-parameter=KeSMSw6SAcsMd56ThdRwRtStFrwdBkwdPosMin.Val
            PA_KeSMSw6SAcsMd57ThdRwRtStBkReclnUpwdDnwdPos_Val: accessed-parameter=KeSMSw6SAcsMd57ThdRwRtStBkReclnUpwdDnwdPos.Val
            PA_KeSMSw6SAcsMd57ThdRwRtStBkReclnUpwdDnwdPosMax_Val: accessed-parameter=KeSMSw6SAcsMd57ThdRwRtStBkReclnUpwdDnwdPosMax.Val
            PA_KeSMSw6SAcsMd57ThdRwRtStBkReclnUpwdDnwdPosMin_Val: accessed-parameter=KeSMSw6SAcsMd57ThdRwRtStBkReclnUpwdDnwdPosMin.Val
            PA_KeSMSw6SAcsMd57ThdRwRtStFrwdBkwdPos_Val: accessed-parameter=KeSMSw6SAcsMd57ThdRwRtStFrwdBkwdPos.Val
            PA_KeSMSw6SAcsMd57ThdRwRtStFrwdBkwdPosMax_Val: accessed-parameter=KeSMSw6SAcsMd57ThdRwRtStFrwdBkwdPosMax.Val
            PA_KeSMSw6SAcsMd57ThdRwRtStFrwdBkwdPosMin_Val: accessed-parameter=KeSMSw6SAcsMd57ThdRwRtStFrwdBkwdPosMin.Val
            PA_KeSMSw6sFamilyMdThdRwRtStFrwdBkwdPos_Val: accessed-parameter=KeSMSw6sFamilyMdThdRwRtStFrwdBkwdPos.Val
            PA_KeSMSw6sFamilyMdThdRwRtStFrwdBkwdPosMax_Val: accessed-parameter=KeSMSw6sFamilyMdThdRwRtStFrwdBkwdPosMax.Val
            PA_KeSMSw6sFamilyMdThdRwRtStFrwdBkwdPosMin_Val: accessed-parameter=KeSMSw6sFamilyMdThdRwRtStFrwdBkwdPosMin.Val
            PA_KeSMSw6sFamilyRMdThdRwRtStFrwdBkwdPos_Val: accessed-parameter=KeSMSw6sFamilyRMdThdRwRtStFrwdBkwdPos.Val
            PA_KeSMSw6sFamilyRMdThdRwRtStFrwdBkwdPosMax_Val: accessed-parameter=KeSMSw6sFamilyRMdThdRwRtStFrwdBkwdPosMax.Val
            PA_KeSMSw6sFamilyRMdThdRwRtStFrwdBkwdPosMin_Val: accessed-parameter=KeSMSw6sFamilyRMdThdRwRtStFrwdBkwdPosMin.Val
            PA_KeSMSw6sLugThdRwRtStBkReclnUpwdDnwdPos_Val: accessed-parameter=KeSMSw6sLugThdRwRtStBkReclnUpwdDnwdPos.Val
            PA_KeSMSw6sLugThdRwRtStBkReclnUpwdDnwdPosMax_Val: accessed-parameter=KeSMSw6sLugThdRwRtStBkReclnUpwdDnwdPosMax.Val
            PA_KeSMSw6sLugThdRwRtStBkReclnUpwdDnwdPosMin_Val: accessed-parameter=KeSMSw6sLugThdRwRtStBkReclnUpwdDnwdPosMin.Val
            PA_KeSMSw6sLugThdRwRtStCshnFldUpwdDnwdPos_Val: accessed-parameter=KeSMSw6sLugThdRwRtStCshnFldUpwdDnwdPos.Val
            PA_KeSMSw6sLugThdRwRtStCshnFldUpwdDnwdPosMax_Val: accessed-parameter=KeSMSw6sLugThdRwRtStCshnFldUpwdDnwdPosMax.Val
            PA_KeSMSw6sLugThdRwRtStCshnFldUpwdDnwdPosMin_Val: accessed-parameter=KeSMSw6sLugThdRwRtStCshnFldUpwdDnwdPosMin.Val
            PA_KeSMSw6sLugThdRwRtStFrwdBkwdPos_Val: accessed-parameter=KeSMSw6sLugThdRwRtStFrwdBkwdPos.Val
            PA_KeSMSw6sLugThdRwRtStFrwdBkwdPosMax_Val: accessed-parameter=KeSMSw6sLugThdRwRtStFrwdBkwdPosMax.Val
            PA_KeSMSw6sLugThdRwRtStFrwdBkwdPosMin_Val: accessed-parameter=KeSMSw6sLugThdRwRtStFrwdBkwdPosMin.Val
            PA_KeSMSw6sVIPThdRwRtStBkReclnUpwdDnwdPos_Val: accessed-parameter=KeSMSw6sVIPThdRwRtStBkReclnUpwdDnwdPos.Val
            PA_KeSMSw6sVIPThdRwRtStBkReclnUpwdDnwdPosMax_Val: accessed-parameter=KeSMSw6sVIPThdRwRtStBkReclnUpwdDnwdPosMax.Val
            PA_KeSMSw6sVIPThdRwRtStBkReclnUpwdDnwdPosMin_Val: accessed-parameter=KeSMSw6sVIPThdRwRtStBkReclnUpwdDnwdPosMin.Val
            PA_KeSMSw6sVIPThdRwRtStFrwdBkwdPos_Val: accessed-parameter=KeSMSw6sVIPThdRwRtStFrwdBkwdPos.Val
            PA_KeSMSw6sVIPThdRwRtStFrwdBkwdPosMax_Val: accessed-parameter=KeSMSw6sVIPThdRwRtStFrwdBkwdPosMax.Val
            PA_KeSMSw6sVIPThdRwRtStFrwdBkwdPosMin_Val: accessed-parameter=KeSMSw6sVIPThdRwRtStFrwdBkwdPosMin.Val
            PA_KeSMSwAcsEntryThdRwRtStBkReclnUpwdDnwdPos_Val: accessed-parameter=KeSMSwAcsEntryThdRwRtStBkReclnUpwdDnwdPos.Val
            PA_KeSMSwAcsEntryThdRwRtStBkReclnUpwdDnwdPosMax_Val: accessed-parameter=KeSMSwAcsEntryThdRwRtStBkReclnUpwdDnwdPosMax.Val
            PA_KeSMSwAcsEntryThdRwRtStBkReclnUpwdDnwdPosMin_Val: accessed-parameter=KeSMSwAcsEntryThdRwRtStBkReclnUpwdDnwdPosMin.Val
            PA_KeSMSwAcsEntryThdRwRtStCshnFldUpwdDnwdPos_Val: accessed-parameter=KeSMSwAcsEntryThdRwRtStCshnFldUpwdDnwdPos.Val
            PA_KeSMSwAcsEntryThdRwRtStCshnFldUpwdDnwdPosMax_Val: accessed-parameter=KeSMSwAcsEntryThdRwRtStCshnFldUpwdDnwdPosMax.Val
            PA_KeSMSwAcsEntryThdRwRtStCshnFldUpwdDnwdPosMin_Val: accessed-parameter=KeSMSwAcsEntryThdRwRtStCshnFldUpwdDnwdPosMin.Val
            PA_KeSMSwAcsEntryThdRwRtStFrwdBkwdPos_Val: accessed-parameter=KeSMSwAcsEntryThdRwRtStFrwdBkwdPos.Val
            PA_KeSMSwAcsEntryThdRwRtStFrwdBkwdPosMax_Val: accessed-parameter=KeSMSwAcsEntryThdRwRtStFrwdBkwdPosMax.Val
            PA_KeSMSwAcsEntryThdRwRtStFrwdBkwdPosMin_Val: accessed-parameter=KeSMSwAcsEntryThdRwRtStFrwdBkwdPosMin.Val
            PA_KeSMSwAcsMd53ThdRwRtBkReclnUpwdDnwdPos_Val: accessed-parameter=KeSMSwAcsMd53ThdRwRtBkReclnUpwdDnwdPos.Val
            PA_KeSMSwAcsMd53ThdRwRtBkReclnUpwdDnwdPosMax_Val: accessed-parameter=KeSMSwAcsMd53ThdRwRtBkReclnUpwdDnwdPosMax.Val
            PA_KeSMSwAcsMd53ThdRwRtBkReclnUpwdDnwdPosMin_Val: accessed-parameter=KeSMSwAcsMd53ThdRwRtBkReclnUpwdDnwdPosMin.Val
            PA_KeSMSwAcsMd53ThdRwRtFldUpwdDnwdPos_Val: accessed-parameter=KeSMSwAcsMd53ThdRwRtFldUpwdDnwdPos.Val
            PA_KeSMSwAcsMd53ThdRwRtFldUpwdDnwdPosMax_Val: accessed-parameter=KeSMSwAcsMd53ThdRwRtFldUpwdDnwdPosMax.Val
            PA_KeSMSwAcsMd53ThdRwRtFldUpwdDnwdPosMin_Val: accessed-parameter=KeSMSwAcsMd53ThdRwRtFldUpwdDnwdPosMin.Val
            PA_KeSMSwAcsMd56ThdRwRtStBkReclnUpwdDnwdPos_Val: accessed-parameter=KeSMSwAcsMd56ThdRwRtStBkReclnUpwdDnwdPos.Val
            PA_KeSMSwAcsMd56ThdRwRtStBkReclnUpwdDnwdPosMax_Val: accessed-parameter=KeSMSwAcsMd56ThdRwRtStBkReclnUpwdDnwdPosMax.Val
            PA_KeSMSwAcsMd56ThdRwRtStBkReclnUpwdDnwdPosMin_Val: accessed-parameter=KeSMSwAcsMd56ThdRwRtStBkReclnUpwdDnwdPosMin.Val
            PA_KeSMSwAcsMd56ThdRwRtStCshnFldUpwdDnwdPos_Val: accessed-parameter=KeSMSwAcsMd56ThdRwRtStCshnFldUpwdDnwdPos.Val
            PA_KeSMSwAcsMd56ThdRwRtStCshnFldUpwdDnwdPosMax_Val: accessed-parameter=KeSMSwAcsMd56ThdRwRtStCshnFldUpwdDnwdPosMax.Val
            PA_KeSMSwAcsMd56ThdRwRtStCshnFldUpwdDnwdPosMin_Val: accessed-parameter=KeSMSwAcsMd56ThdRwRtStCshnFldUpwdDnwdPosMin.Val
            PA_KeSMSwAcsMd56ThdRwRtStFrwdBkwdPos_Val: accessed-parameter=KeSMSwAcsMd56ThdRwRtStFrwdBkwdPos.Val
            PA_KeSMSwAcsMd56ThdRwRtStFrwdBkwdPosMax_Val: accessed-parameter=KeSMSwAcsMd56ThdRwRtStFrwdBkwdPosMax.Val
            PA_KeSMSwAcsMd56ThdRwRtStFrwdBkwdPosMin_Val: accessed-parameter=KeSMSwAcsMd56ThdRwRtStFrwdBkwdPosMin.Val
            PA_KeSMSwAcsMd57ThdRwRtStBkReclnUpwdDnwdPos_Val: accessed-parameter=KeSMSwAcsMd57ThdRwRtStBkReclnUpwdDnwdPos.Val
            PA_KeSMSwAcsMd57ThdRwRtStBkReclnUpwdDnwdPosMax_Val: accessed-parameter=KeSMSwAcsMd57ThdRwRtStBkReclnUpwdDnwdPosMax.Val
            PA_KeSMSwAcsMd57ThdRwRtStBkReclnUpwdDnwdPosMin_Val: accessed-parameter=KeSMSwAcsMd57ThdRwRtStBkReclnUpwdDnwdPosMin.Val
            PA_KeSMSwAcsMd57ThdRwRtStFrwdBkwdPos_Val: accessed-parameter=KeSMSwAcsMd57ThdRwRtStFrwdBkwdPos.Val
            PA_KeSMSwAcsMd57ThdRwRtStFrwdBkwdPosMax_Val: accessed-parameter=KeSMSwAcsMd57ThdRwRtStFrwdBkwdPosMax.Val
            PA_KeSMSwAcsMd57ThdRwRtStFrwdBkwdPosMin_Val: accessed-parameter=KeSMSwAcsMd57ThdRwRtStFrwdBkwdPosMin.Val
            PA_KeSMSwAcsMd7ThdRwRtStBkReclnUpwdDnwdPos_Val: accessed-parameter=KeSMSwAcsMd7ThdRwRtStBkReclnUpwdDnwdPos.Val
            PA_KeSMSwAcsMd7ThdRwRtStBkReclnUpwdDnwdPosMax_Val: accessed-parameter=KeSMSwAcsMd7ThdRwRtStBkReclnUpwdDnwdPosMax.Val
            PA_KeSMSwAcsMd7ThdRwRtStBkReclnUpwdDnwdPosMin_Val: accessed-parameter=KeSMSwAcsMd7ThdRwRtStBkReclnUpwdDnwdPosMin.Val
            PA_KeSMSwAcsMd7ThdRwRtStCshnFldUpwdDnwdPos_Val: accessed-parameter=KeSMSwAcsMd7ThdRwRtStCshnFldUpwdDnwdPos.Val
            PA_KeSMSwAcsMd7ThdRwRtStCshnFldUpwdDnwdPosMax_Val: accessed-parameter=KeSMSwAcsMd7ThdRwRtStCshnFldUpwdDnwdPosMax.Val
            PA_KeSMSwAcsMd7ThdRwRtStCshnFldUpwdDnwdPosMin_Val: accessed-parameter=KeSMSwAcsMd7ThdRwRtStCshnFldUpwdDnwdPosMin.Val
            PA_KeSMSwAcsMd7ThdRwRtStFrwdBkwdPos_Val: accessed-parameter=KeSMSwAcsMd7ThdRwRtStFrwdBkwdPos.Val
            PA_KeSMSwAcsMd7ThdRwRtStFrwdBkwdPosMax_Val: accessed-parameter=KeSMSwAcsMd7ThdRwRtStFrwdBkwdPosMax.Val
            PA_KeSMSwAcsMd7ThdRwRtStFrwdBkwdPosMin_Val: accessed-parameter=KeSMSwAcsMd7ThdRwRtStFrwdBkwdPosMin.Val
            PA_KeSMSwFamilyMdThdRwRtStFrwdBkwdPos_Val: accessed-parameter=KeSMSwFamilyMdThdRwRtStFrwdBkwdPos.Val
            PA_KeSMSwFamilyMdThdRwRtStFrwdBkwdPosMax_Val: accessed-parameter=KeSMSwFamilyMdThdRwRtStFrwdBkwdPosMax.Val
            PA_KeSMSwFamilyMdThdRwRtStFrwdBkwdPosMin_Val: accessed-parameter=KeSMSwFamilyMdThdRwRtStFrwdBkwdPosMin.Val
            PA_KeSMSwFamilyRMdThdRwRtStFrwdBkwdPos_Val: accessed-parameter=KeSMSwFamilyRMdThdRwRtStFrwdBkwdPos.Val
            PA_KeSMSwFamilyRMdThdRwRtStFrwdBkwdPosMax_Val: accessed-parameter=KeSMSwFamilyRMdThdRwRtStFrwdBkwdPosMax.Val
            PA_KeSMSwFamilyRMdThdRwRtStFrwdBkwdPosMin_Val: accessed-parameter=KeSMSwFamilyRMdThdRwRtStFrwdBkwdPosMin.Val
            PA_KeSMSwLugThdRwRtStBkReclnUpwdDnwdPos_Val: accessed-parameter=KeSMSwLugThdRwRtStBkReclnUpwdDnwdPos.Val
            PA_KeSMSwLugThdRwRtStBkReclnUpwdDnwdPosMax_Val: accessed-parameter=KeSMSwLugThdRwRtStBkReclnUpwdDnwdPosMax.Val
            PA_KeSMSwLugThdRwRtStBkReclnUpwdDnwdPosMin_Val: accessed-parameter=KeSMSwLugThdRwRtStBkReclnUpwdDnwdPosMin.Val
            PA_KeSMSwLugThdRwRtStCshnFldUpwdDnwdPos_Val: accessed-parameter=KeSMSwLugThdRwRtStCshnFldUpwdDnwdPos.Val
            PA_KeSMSwLugThdRwRtStCshnFldUpwdDnwdPosMax_Val: accessed-parameter=KeSMSwLugThdRwRtStCshnFldUpwdDnwdPosMax.Val
            PA_KeSMSwLugThdRwRtStCshnFldUpwdDnwdPosMin_Val: accessed-parameter=KeSMSwLugThdRwRtStCshnFldUpwdDnwdPosMin.Val
            PA_KeSMSwLugThdRwRtStFrwdBkwdPos_Val: accessed-parameter=KeSMSwLugThdRwRtStFrwdBkwdPos.Val
            PA_KeSMSwLugThdRwRtStFrwdBkwdPosMax_Val: accessed-parameter=KeSMSwLugThdRwRtStFrwdBkwdPosMax.Val
            PA_KeSMSwLugThdRwRtStFrwdBkwdPosMin_Val: accessed-parameter=KeSMSwLugThdRwRtStFrwdBkwdPosMin.Val
            PA_KeSMSwVIPThdRwRtStBkReclnUpwdDnwdPos_Val: accessed-parameter=KeSMSwVIPThdRwRtStBkReclnUpwdDnwdPos.Val
            PA_KeSMSwVIPThdRwRtStBkReclnUpwdDnwdPosMax_Val: accessed-parameter=KeSMSwVIPThdRwRtStBkReclnUpwdDnwdPosMax.Val
            PA_KeSMSwVIPThdRwRtStBkReclnUpwdDnwdPosMin_Val: accessed-parameter=KeSMSwVIPThdRwRtStBkReclnUpwdDnwdPosMin.Val
            PA_KeSMSwVIPThdRwRtStFrwdBkwdPos_Val: accessed-parameter=KeSMSwVIPThdRwRtStFrwdBkwdPos.Val
            PA_KeSMSwVIPThdRwRtStFrwdBkwdPosMax_Val: accessed-parameter=KeSMSwVIPThdRwRtStFrwdBkwdPosMax.Val
            PA_KeSMSwVIPThdRwRtStFrwdBkwdPosMin_Val: accessed-parameter=KeSMSwVIPThdRwRtStFrwdBkwdPosMin.Val
          sync call SC_Md58TrgtPos_Get: operation=Md58TrgtPos.Get, timeout=0
          sync call SC_VIPRExit557TrgtPos_Get: operation=VIPRExit557TrgtPos.Get, timeout=0
        ThrdRwRtStCshnFldTrgtPosSelc_1_Cal
          data-receive-point-by-arguments:
            5 x access:
              REC_IfVeSMSuThdRwRtStCshnFldUpwdDnwdPos_Val: accessed-variable=IfVeSMSuThdRwRtStCshnFldUpwdDnwdPos.Val
              REC_StNumFlg_Is4s: accessed-variable=StNumFlg.Is4s
              REC_StNumFlg_Is6s: accessed-variable=StNumFlg.Is6s
              REC_StNumFlg_Is6s7s: accessed-variable=StNumFlg.Is6s7s
              REC_StNumFlg_Is7s: accessed-variable=StNumFlg.Is7s
          data-send-points:
            5 x access:
              SEND_EZER3RCshnFldTrgtPosCalib_TrgtPosArray: accessed-variable=EZER3RCshnFldTrgtPosCalib.TrgtPosArray
              SEND_LugRR3RCshnFldTrgtPosCalib_TrgtPosArray: accessed-variable=LugRR3RCshnFldTrgtPosCalib.TrgtPosArray
              SEND_Md28R3RCshnFldTrgtPosCalib_TrgtPosArray: accessed-variable=Md28R3RCshnFldTrgtPosCalib.TrgtPosArray
              SEND_Md53CshnFldTrgtPosCalib_TrgtPosArray: accessed-variable=Md53CshnFldTrgtPosCalib.TrgtPosArray
              SEND_Md56R3RCshnFldTrgtPosCalib_TrgtPosArray: accessed-variable=Md56R3RCshnFldTrgtPosCalib.TrgtPosArray
          102 x parameter access:
            PA_KeSMSw6sAcsEntryThdRwRtStBkReclnUpwdDnwdPos_Val: accessed-parameter=KeSMSw6sAcsEntryThdRwRtStBkReclnUpwdDnwdPos.Val
            PA_KeSMSw6sAcsEntryThdRwRtStBkReclnUpwdDnwdPosMax_Val: accessed-parameter=KeSMSw6sAcsEntryThdRwRtStBkReclnUpwdDnwdPosMax.Val
            PA_KeSMSw6sAcsEntryThdRwRtStBkReclnUpwdDnwdPosMin_Val: accessed-parameter=KeSMSw6sAcsEntryThdRwRtStBkReclnUpwdDnwdPosMin.Val
            PA_KeSMSw6sAcsEntryThdRwRtStCshnFldUpwdDnwdPos_Val: accessed-parameter=KeSMSw6sAcsEntryThdRwRtStCshnFldUpwdDnwdPos.Val
            PA_KeSMSw6sAcsEntryThdRwRtStCshnFldUpwdDnwdPosMax_Val: accessed-parameter=KeSMSw6sAcsEntryThdRwRtStCshnFldUpwdDnwdPosMax.Val
            PA_KeSMSw6sAcsEntryThdRwRtStCshnFldUpwdDnwdPosMin_Val: accessed-parameter=KeSMSw6sAcsEntryThdRwRtStCshnFldUpwdDnwdPosMin.Val
            PA_KeSMSw6sAcsEntryThdRwRtStFrwdBkwdPos_Val: accessed-parameter=KeSMSw6sAcsEntryThdRwRtStFrwdBkwdPos.Val
            PA_KeSMSw6sAcsEntryThdRwRtStFrwdBkwdPosMax_Val: accessed-parameter=KeSMSw6sAcsEntryThdRwRtStFrwdBkwdPosMax.Val
            PA_KeSMSw6sAcsEntryThdRwRtStFrwdBkwdPosMin_Val: accessed-parameter=KeSMSw6sAcsEntryThdRwRtStFrwdBkwdPosMin.Val
            PA_KeSMSw6SAcsMd56ThdRwRtStBkReclnUpwdDnwdPos_Val: accessed-parameter=KeSMSw6SAcsMd56ThdRwRtStBkReclnUpwdDnwdPos.Val
            PA_KeSMSw6SAcsMd56ThdRwRtStBkReclnUpwdDnwdPosMax_Val: accessed-parameter=KeSMSw6SAcsMd56ThdRwRtStBkReclnUpwdDnwdPosMax.Val
            PA_KeSMSw6SAcsMd56ThdRwRtStBkReclnUpwdDnwdPosMin_Val: accessed-parameter=KeSMSw6SAcsMd56ThdRwRtStBkReclnUpwdDnwdPosMin.Val
            PA_KeSMSw6SAcsMd56ThdRwRtStFrwdBkwdPos_Val: accessed-parameter=KeSMSw6SAcsMd56ThdRwRtStFrwdBkwdPos.Val
            PA_KeSMSw6SAcsMd56ThdRwRtStFrwdBkwdPosMax_Val: accessed-parameter=KeSMSw6SAcsMd56ThdRwRtStFrwdBkwdPosMax.Val
            PA_KeSMSw6SAcsMd56ThdRwRtStFrwdBkwdPosMin_Val: accessed-parameter=KeSMSw6SAcsMd56ThdRwRtStFrwdBkwdPosMin.Val
            PA_KeSMSw6SAcsMd57ThdRwRtStBkReclnUpwdDnwdPos_Val: accessed-parameter=KeSMSw6SAcsMd57ThdRwRtStBkReclnUpwdDnwdPos.Val
            PA_KeSMSw6SAcsMd57ThdRwRtStBkReclnUpwdDnwdPosMax_Val: accessed-parameter=KeSMSw6SAcsMd57ThdRwRtStBkReclnUpwdDnwdPosMax.Val
            PA_KeSMSw6SAcsMd57ThdRwRtStBkReclnUpwdDnwdPosMin_Val: accessed-parameter=KeSMSw6SAcsMd57ThdRwRtStBkReclnUpwdDnwdPosMin.Val
            PA_KeSMSw6SAcsMd57ThdRwRtStFrwdBkwdPos_Val: accessed-parameter=KeSMSw6SAcsMd57ThdRwRtStFrwdBkwdPos.Val
            PA_KeSMSw6SAcsMd57ThdRwRtStFrwdBkwdPosMax_Val: accessed-parameter=KeSMSw6SAcsMd57ThdRwRtStFrwdBkwdPosMax.Val
            PA_KeSMSw6SAcsMd57ThdRwRtStFrwdBkwdPosMin_Val: accessed-parameter=KeSMSw6SAcsMd57ThdRwRtStFrwdBkwdPosMin.Val
            PA_KeSMSw6sFamilyMdThdRwRtStFrwdBkwdPos_Val: accessed-parameter=KeSMSw6sFamilyMdThdRwRtStFrwdBkwdPos.Val
            PA_KeSMSw6sFamilyMdThdRwRtStFrwdBkwdPosMax_Val: accessed-parameter=KeSMSw6sFamilyMdThdRwRtStFrwdBkwdPosMax.Val
            PA_KeSMSw6sFamilyMdThdRwRtStFrwdBkwdPosMin_Val: accessed-parameter=KeSMSw6sFamilyMdThdRwRtStFrwdBkwdPosMin.Val
            PA_KeSMSw6sFamilyRMdThdRwRtStFrwdBkwdPos_Val: accessed-parameter=KeSMSw6sFamilyRMdThdRwRtStFrwdBkwdPos.Val
            PA_KeSMSw6sFamilyRMdThdRwRtStFrwdBkwdPosMax_Val: accessed-parameter=KeSMSw6sFamilyRMdThdRwRtStFrwdBkwdPosMax.Val
            PA_KeSMSw6sFamilyRMdThdRwRtStFrwdBkwdPosMin_Val: accessed-parameter=KeSMSw6sFamilyRMdThdRwRtStFrwdBkwdPosMin.Val
            PA_KeSMSw6sLugThdRwRtStBkReclnUpwdDnwdPos_Val: accessed-parameter=KeSMSw6sLugThdRwRtStBkReclnUpwdDnwdPos.Val
            PA_KeSMSw6sLugThdRwRtStBkReclnUpwdDnwdPosMax_Val: accessed-parameter=KeSMSw6sLugThdRwRtStBkReclnUpwdDnwdPosMax.Val
            PA_KeSMSw6sLugThdRwRtStBkReclnUpwdDnwdPosMin_Val: accessed-parameter=KeSMSw6sLugThdRwRtStBkReclnUpwdDnwdPosMin.Val
            PA_KeSMSw6sLugThdRwRtStCshnFldUpwdDnwdPos_Val: accessed-parameter=KeSMSw6sLugThdRwRtStCshnFldUpwdDnwdPos.Val
            PA_KeSMSw6sLugThdRwRtStCshnFldUpwdDnwdPosMax_Val: accessed-parameter=KeSMSw6sLugThdRwRtStCshnFldUpwdDnwdPosMax.Val
            PA_KeSMSw6sLugThdRwRtStCshnFldUpwdDnwdPosMin_Val: accessed-parameter=KeSMSw6sLugThdRwRtStCshnFldUpwdDnwdPosMin.Val
            PA_KeSMSw6sLugThdRwRtStFrwdBkwdPos_Val: accessed-parameter=KeSMSw6sLugThdRwRtStFrwdBkwdPos.Val
            PA_KeSMSw6sLugThdRwRtStFrwdBkwdPosMax_Val: accessed-parameter=KeSMSw6sLugThdRwRtStFrwdBkwdPosMax.Val
            PA_KeSMSw6sLugThdRwRtStFrwdBkwdPosMin_Val: accessed-parameter=KeSMSw6sLugThdRwRtStFrwdBkwdPosMin.Val
            PA_KeSMSw6sVIPThdRwRtStBkReclnUpwdDnwdPos_Val: accessed-parameter=KeSMSw6sVIPThdRwRtStBkReclnUpwdDnwdPos.Val
            PA_KeSMSw6sVIPThdRwRtStBkReclnUpwdDnwdPosMax_Val: accessed-parameter=KeSMSw6sVIPThdRwRtStBkReclnUpwdDnwdPosMax.Val
            PA_KeSMSw6sVIPThdRwRtStBkReclnUpwdDnwdPosMin_Val: accessed-parameter=KeSMSw6sVIPThdRwRtStBkReclnUpwdDnwdPosMin.Val
            PA_KeSMSw6sVIPThdRwRtStFrwdBkwdPos_Val: accessed-parameter=KeSMSw6sVIPThdRwRtStFrwdBkwdPos.Val
            PA_KeSMSw6sVIPThdRwRtStFrwdBkwdPosMax_Val: accessed-parameter=KeSMSw6sVIPThdRwRtStFrwdBkwdPosMax.Val
            PA_KeSMSw6sVIPThdRwRtStFrwdBkwdPosMin_Val: accessed-parameter=KeSMSw6sVIPThdRwRtStFrwdBkwdPosMin.Val
            PA_KeSMSwAcsEntryThdRwRtStBkReclnUpwdDnwdPos_Val: accessed-parameter=KeSMSwAcsEntryThdRwRtStBkReclnUpwdDnwdPos.Val
            PA_KeSMSwAcsEntryThdRwRtStBkReclnUpwdDnwdPosMax_Val: accessed-parameter=KeSMSwAcsEntryThdRwRtStBkReclnUpwdDnwdPosMax.Val
            PA_KeSMSwAcsEntryThdRwRtStBkReclnUpwdDnwdPosMin_Val: accessed-parameter=KeSMSwAcsEntryThdRwRtStBkReclnUpwdDnwdPosMin.Val
            PA_KeSMSwAcsEntryThdRwRtStCshnFldUpwdDnwdPos_Val: accessed-parameter=KeSMSwAcsEntryThdRwRtStCshnFldUpwdDnwdPos.Val
            PA_KeSMSwAcsEntryThdRwRtStCshnFldUpwdDnwdPosMax_Val: accessed-parameter=KeSMSwAcsEntryThdRwRtStCshnFldUpwdDnwdPosMax.Val
            PA_KeSMSwAcsEntryThdRwRtStCshnFldUpwdDnwdPosMin_Val: accessed-parameter=KeSMSwAcsEntryThdRwRtStCshnFldUpwdDnwdPosMin.Val
            PA_KeSMSwAcsEntryThdRwRtStFrwdBkwdPos_Val: accessed-parameter=KeSMSwAcsEntryThdRwRtStFrwdBkwdPos.Val
            PA_KeSMSwAcsEntryThdRwRtStFrwdBkwdPosMax_Val: accessed-parameter=KeSMSwAcsEntryThdRwRtStFrwdBkwdPosMax.Val
            PA_KeSMSwAcsEntryThdRwRtStFrwdBkwdPosMin_Val: accessed-parameter=KeSMSwAcsEntryThdRwRtStFrwdBkwdPosMin.Val
            PA_KeSMSwAcsMd53ThdRwRtBkReclnUpwdDnwdPos_Val: accessed-parameter=KeSMSwAcsMd53ThdRwRtBkReclnUpwdDnwdPos.Val
            PA_KeSMSwAcsMd53ThdRwRtBkReclnUpwdDnwdPosMax_Val: accessed-parameter=KeSMSwAcsMd53ThdRwRtBkReclnUpwdDnwdPosMax.Val
            PA_KeSMSwAcsMd53ThdRwRtBkReclnUpwdDnwdPosMin_Val: accessed-parameter=KeSMSwAcsMd53ThdRwRtBkReclnUpwdDnwdPosMin.Val
            PA_KeSMSwAcsMd53ThdRwRtFldUpwdDnwdPos_Val: accessed-parameter=KeSMSwAcsMd53ThdRwRtFldUpwdDnwdPos.Val
            PA_KeSMSwAcsMd53ThdRwRtFldUpwdDnwdPosMax_Val: accessed-parameter=KeSMSwAcsMd53ThdRwRtFldUpwdDnwdPosMax.Val
            PA_KeSMSwAcsMd53ThdRwRtFldUpwdDnwdPosMin_Val: accessed-parameter=KeSMSwAcsMd53ThdRwRtFldUpwdDnwdPosMin.Val
            PA_KeSMSwAcsMd56ThdRwRtStBkReclnUpwdDnwdPos_Val: accessed-parameter=KeSMSwAcsMd56ThdRwRtStBkReclnUpwdDnwdPos.Val
            PA_KeSMSwAcsMd56ThdRwRtStBkReclnUpwdDnwdPosMax_Val: accessed-parameter=KeSMSwAcsMd56ThdRwRtStBkReclnUpwdDnwdPosMax.Val
            PA_KeSMSwAcsMd56ThdRwRtStBkReclnUpwdDnwdPosMin_Val: accessed-parameter=KeSMSwAcsMd56ThdRwRtStBkReclnUpwdDnwdPosMin.Val
            PA_KeSMSwAcsMd56ThdRwRtStCshnFldUpwdDnwdPos_Val: accessed-parameter=KeSMSwAcsMd56ThdRwRtStCshnFldUpwdDnwdPos.Val
            PA_KeSMSwAcsMd56ThdRwRtStCshnFldUpwdDnwdPosMax_Val: accessed-parameter=KeSMSwAcsMd56ThdRwRtStCshnFldUpwdDnwdPosMax.Val
            PA_KeSMSwAcsMd56ThdRwRtStCshnFldUpwdDnwdPosMin_Val: accessed-parameter=KeSMSwAcsMd56ThdRwRtStCshnFldUpwdDnwdPosMin.Val
            PA_KeSMSwAcsMd56ThdRwRtStFrwdBkwdPos_Val: accessed-parameter=KeSMSwAcsMd56ThdRwRtStFrwdBkwdPos.Val
            PA_KeSMSwAcsMd56ThdRwRtStFrwdBkwdPosMax_Val: accessed-parameter=KeSMSwAcsMd56ThdRwRtStFrwdBkwdPosMax.Val
            PA_KeSMSwAcsMd56ThdRwRtStFrwdBkwdPosMin_Val: accessed-parameter=KeSMSwAcsMd56ThdRwRtStFrwdBkwdPosMin.Val
            PA_KeSMSwAcsMd57ThdRwRtStBkReclnUpwdDnwdPos_Val: accessed-parameter=KeSMSwAcsMd57ThdRwRtStBkReclnUpwdDnwdPos.Val
            PA_KeSMSwAcsMd57ThdRwRtStBkReclnUpwdDnwdPosMax_Val: accessed-parameter=KeSMSwAcsMd57ThdRwRtStBkReclnUpwdDnwdPosMax.Val
            PA_KeSMSwAcsMd57ThdRwRtStBkReclnUpwdDnwdPosMin_Val: accessed-parameter=KeSMSwAcsMd57ThdRwRtStBkReclnUpwdDnwdPosMin.Val
            PA_KeSMSwAcsMd57ThdRwRtStFrwdBkwdPos_Val: accessed-parameter=KeSMSwAcsMd57ThdRwRtStFrwdBkwdPos.Val
            PA_KeSMSwAcsMd57ThdRwRtStFrwdBkwdPosMax_Val: accessed-parameter=KeSMSwAcsMd57ThdRwRtStFrwdBkwdPosMax.Val
            PA_KeSMSwAcsMd57ThdRwRtStFrwdBkwdPosMin_Val: accessed-parameter=KeSMSwAcsMd57ThdRwRtStFrwdBkwdPosMin.Val
            PA_KeSMSwAcsMd7ThdRwRtStBkReclnUpwdDnwdPos_Val: accessed-parameter=KeSMSwAcsMd7ThdRwRtStBkReclnUpwdDnwdPos.Val
            PA_KeSMSwAcsMd7ThdRwRtStBkReclnUpwdDnwdPosMax_Val: accessed-parameter=KeSMSwAcsMd7ThdRwRtStBkReclnUpwdDnwdPosMax.Val
            PA_KeSMSwAcsMd7ThdRwRtStBkReclnUpwdDnwdPosMin_Val: accessed-parameter=KeSMSwAcsMd7ThdRwRtStBkReclnUpwdDnwdPosMin.Val
            PA_KeSMSwAcsMd7ThdRwRtStCshnFldUpwdDnwdPos_Val: accessed-parameter=KeSMSwAcsMd7ThdRwRtStCshnFldUpwdDnwdPos.Val
            PA_KeSMSwAcsMd7ThdRwRtStCshnFldUpwdDnwdPosMax_Val: accessed-parameter=KeSMSwAcsMd7ThdRwRtStCshnFldUpwdDnwdPosMax.Val
            PA_KeSMSwAcsMd7ThdRwRtStCshnFldUpwdDnwdPosMin_Val: accessed-parameter=KeSMSwAcsMd7ThdRwRtStCshnFldUpwdDnwdPosMin.Val
            PA_KeSMSwAcsMd7ThdRwRtStFrwdBkwdPos_Val: accessed-parameter=KeSMSwAcsMd7ThdRwRtStFrwdBkwdPos.Val
            PA_KeSMSwAcsMd7ThdRwRtStFrwdBkwdPosMax_Val: accessed-parameter=KeSMSwAcsMd7ThdRwRtStFrwdBkwdPosMax.Val
            PA_KeSMSwAcsMd7ThdRwRtStFrwdBkwdPosMin_Val: accessed-parameter=KeSMSwAcsMd7ThdRwRtStFrwdBkwdPosMin.Val
            PA_KeSMSwFamilyMdThdRwRtStFrwdBkwdPos_Val: accessed-parameter=KeSMSwFamilyMdThdRwRtStFrwdBkwdPos.Val
            PA_KeSMSwFamilyMdThdRwRtStFrwdBkwdPosMax_Val: accessed-parameter=KeSMSwFamilyMdThdRwRtStFrwdBkwdPosMax.Val
            PA_KeSMSwFamilyMdThdRwRtStFrwdBkwdPosMin_Val: accessed-parameter=KeSMSwFamilyMdThdRwRtStFrwdBkwdPosMin.Val
            PA_KeSMSwFamilyRMdThdRwRtStFrwdBkwdPos_Val: accessed-parameter=KeSMSwFamilyRMdThdRwRtStFrwdBkwdPos.Val
            PA_KeSMSwFamilyRMdThdRwRtStFrwdBkwdPosMax_Val: accessed-parameter=KeSMSwFamilyRMdThdRwRtStFrwdBkwdPosMax.Val
            PA_KeSMSwFamilyRMdThdRwRtStFrwdBkwdPosMin_Val: accessed-parameter=KeSMSwFamilyRMdThdRwRtStFrwdBkwdPosMin.Val
            PA_KeSMSwLugThdRwRtStBkReclnUpwdDnwdPos_Val: accessed-parameter=KeSMSwLugThdRwRtStBkReclnUpwdDnwdPos.Val
            PA_KeSMSwLugThdRwRtStBkReclnUpwdDnwdPosMax_Val: accessed-parameter=KeSMSwLugThdRwRtStBkReclnUpwdDnwdPosMax.Val
            PA_KeSMSwLugThdRwRtStBkReclnUpwdDnwdPosMin_Val: accessed-parameter=KeSMSwLugThdRwRtStBkReclnUpwdDnwdPosMin.Val
            PA_KeSMSwLugThdRwRtStCshnFldUpwdDnwdPos_Val: accessed-parameter=KeSMSwLugThdRwRtStCshnFldUpwdDnwdPos.Val
            PA_KeSMSwLugThdRwRtStCshnFldUpwdDnwdPosMax_Val: accessed-parameter=KeSMSwLugThdRwRtStCshnFldUpwdDnwdPosMax.Val
            PA_KeSMSwLugThdRwRtStCshnFldUpwdDnwdPosMin_Val: accessed-parameter=KeSMSwLugThdRwRtStCshnFldUpwdDnwdPosMin.Val
            PA_KeSMSwLugThdRwRtStFrwdBkwdPos_Val: accessed-parameter=KeSMSwLugThdRwRtStFrwdBkwdPos.Val
            PA_KeSMSwLugThdRwRtStFrwdBkwdPosMax_Val: accessed-parameter=KeSMSwLugThdRwRtStFrwdBkwdPosMax.Val
            PA_KeSMSwLugThdRwRtStFrwdBkwdPosMin_Val: accessed-parameter=KeSMSwLugThdRwRtStFrwdBkwdPosMin.Val
            PA_KeSMSwVIPThdRwRtStBkReclnUpwdDnwdPos_Val: accessed-parameter=KeSMSwVIPThdRwRtStBkReclnUpwdDnwdPos.Val
            PA_KeSMSwVIPThdRwRtStBkReclnUpwdDnwdPosMax_Val: accessed-parameter=KeSMSwVIPThdRwRtStBkReclnUpwdDnwdPosMax.Val
            PA_KeSMSwVIPThdRwRtStBkReclnUpwdDnwdPosMin_Val: accessed-parameter=KeSMSwVIPThdRwRtStBkReclnUpwdDnwdPosMin.Val
            PA_KeSMSwVIPThdRwRtStFrwdBkwdPos_Val: accessed-parameter=KeSMSwVIPThdRwRtStFrwdBkwdPos.Val
            PA_KeSMSwVIPThdRwRtStFrwdBkwdPosMax_Val: accessed-parameter=KeSMSwVIPThdRwRtStFrwdBkwdPosMax.Val
            PA_KeSMSwVIPThdRwRtStFrwdBkwdPosMin_Val: accessed-parameter=KeSMSwVIPThdRwRtStFrwdBkwdPosMin.Val
        ThrdRwRtStFwdBkwdTrgtPosSelc_1_Cal
          data-receive-point-by-arguments:
            5 x access:
              REC_IfVeSMSuThdRwRtStCshnFldUpwdDnwdPos_Val: accessed-variable=IfVeSMSuThdRwRtStCshnFldUpwdDnwdPos.Val
              REC_StNumFlg_Is4s: accessed-variable=StNumFlg.Is4s
              REC_StNumFlg_Is6s: accessed-variable=StNumFlg.Is6s
              REC_StNumFlg_Is6s7s: accessed-variable=StNumFlg.Is6s7s
              REC_StNumFlg_Is7s: accessed-variable=StNumFlg.Is7s
          data-send-points:
            8 x access:
              SEND_EZER3RFwdBkwdTrgtPosCalib_TrgtPosArray: accessed-variable=EZER3RFwdBkwdTrgtPosCalib.TrgtPosArray
              SEND_FAMLYLR3RFwdBkwdTrgtPosCalib_TrgtPosArray: accessed-variable=FAMLYLR3RFwdBkwdTrgtPosCalib.TrgtPosArray
              SEND_FAMLYRR3RFwdBkwdTrgtPosCalib_TrgtPosArray: accessed-variable=FAMLYRR3RFwdBkwdTrgtPosCalib.TrgtPosArray
              SEND_LugRR3RFwdBkwdTrgtPosCalib_TrgtPosArray: accessed-variable=LugRR3RFwdBkwdTrgtPosCalib.TrgtPosArray
              SEND_Md28R3RFwdBkwdTrgtPosCalib_TrgtPosArray: accessed-variable=Md28R3RFwdBkwdTrgtPosCalib.TrgtPosArray
              SEND_Md56R3RFwdBkwdTrgtPosCalib_TrgtPosArray: accessed-variable=Md56R3RFwdBkwdTrgtPosCalib.TrgtPosArray
              SEND_Md57R3RFwdBkwdTrgtPosCalib_TrgtPosArray: accessed-variable=Md57R3RFwdBkwdTrgtPosCalib.TrgtPosArray
              SEND_VIPR3RFwdBkwdTrgtPosCalib_TrgtPosArray: accessed-variable=VIPR3RFwdBkwdTrgtPosCalib.TrgtPosArray
          102 x parameter access:
            PA_KeSMSw6sAcsEntryThdRwRtStBkReclnUpwdDnwdPos_Val: accessed-parameter=KeSMSw6sAcsEntryThdRwRtStBkReclnUpwdDnwdPos.Val
            PA_KeSMSw6sAcsEntryThdRwRtStBkReclnUpwdDnwdPosMax_Val: accessed-parameter=KeSMSw6sAcsEntryThdRwRtStBkReclnUpwdDnwdPosMax.Val
            PA_KeSMSw6sAcsEntryThdRwRtStBkReclnUpwdDnwdPosMin_Val: accessed-parameter=KeSMSw6sAcsEntryThdRwRtStBkReclnUpwdDnwdPosMin.Val
            PA_KeSMSw6sAcsEntryThdRwRtStCshnFldUpwdDnwdPos_Val: accessed-parameter=KeSMSw6sAcsEntryThdRwRtStCshnFldUpwdDnwdPos.Val
            PA_KeSMSw6sAcsEntryThdRwRtStCshnFldUpwdDnwdPosMax_Val: accessed-parameter=KeSMSw6sAcsEntryThdRwRtStCshnFldUpwdDnwdPosMax.Val
            PA_KeSMSw6sAcsEntryThdRwRtStCshnFldUpwdDnwdPosMin_Val: accessed-parameter=KeSMSw6sAcsEntryThdRwRtStCshnFldUpwdDnwdPosMin.Val
            PA_KeSMSw6sAcsEntryThdRwRtStFrwdBkwdPos_Val: accessed-parameter=KeSMSw6sAcsEntryThdRwRtStFrwdBkwdPos.Val
            PA_KeSMSw6sAcsEntryThdRwRtStFrwdBkwdPosMax_Val: accessed-parameter=KeSMSw6sAcsEntryThdRwRtStFrwdBkwdPosMax.Val
            PA_KeSMSw6sAcsEntryThdRwRtStFrwdBkwdPosMin_Val: accessed-parameter=KeSMSw6sAcsEntryThdRwRtStFrwdBkwdPosMin.Val
            PA_KeSMSw6SAcsMd56ThdRwRtStBkReclnUpwdDnwdPos_Val: accessed-parameter=KeSMSw6SAcsMd56ThdRwRtStBkReclnUpwdDnwdPos.Val
            PA_KeSMSw6SAcsMd56ThdRwRtStBkReclnUpwdDnwdPosMax_Val: accessed-parameter=KeSMSw6SAcsMd56ThdRwRtStBkReclnUpwdDnwdPosMax.Val
            PA_KeSMSw6SAcsMd56ThdRwRtStBkReclnUpwdDnwdPosMin_Val: accessed-parameter=KeSMSw6SAcsMd56ThdRwRtStBkReclnUpwdDnwdPosMin.Val
            PA_KeSMSw6SAcsMd56ThdRwRtStFrwdBkwdPos_Val: accessed-parameter=KeSMSw6SAcsMd56ThdRwRtStFrwdBkwdPos.Val
            PA_KeSMSw6SAcsMd56ThdRwRtStFrwdBkwdPosMax_Val: accessed-parameter=KeSMSw6SAcsMd56ThdRwRtStFrwdBkwdPosMax.Val
            PA_KeSMSw6SAcsMd56ThdRwRtStFrwdBkwdPosMin_Val: accessed-parameter=KeSMSw6SAcsMd56ThdRwRtStFrwdBkwdPosMin.Val
            PA_KeSMSw6SAcsMd57ThdRwRtStBkReclnUpwdDnwdPos_Val: accessed-parameter=KeSMSw6SAcsMd57ThdRwRtStBkReclnUpwdDnwdPos.Val
            PA_KeSMSw6SAcsMd57ThdRwRtStBkReclnUpwdDnwdPosMax_Val: accessed-parameter=KeSMSw6SAcsMd57ThdRwRtStBkReclnUpwdDnwdPosMax.Val
            PA_KeSMSw6SAcsMd57ThdRwRtStBkReclnUpwdDnwdPosMin_Val: accessed-parameter=KeSMSw6SAcsMd57ThdRwRtStBkReclnUpwdDnwdPosMin.Val
            PA_KeSMSw6SAcsMd57ThdRwRtStFrwdBkwdPos_Val: accessed-parameter=KeSMSw6SAcsMd57ThdRwRtStFrwdBkwdPos.Val
            PA_KeSMSw6SAcsMd57ThdRwRtStFrwdBkwdPosMax_Val: accessed-parameter=KeSMSw6SAcsMd57ThdRwRtStFrwdBkwdPosMax.Val
            PA_KeSMSw6SAcsMd57ThdRwRtStFrwdBkwdPosMin_Val: accessed-parameter=KeSMSw6SAcsMd57ThdRwRtStFrwdBkwdPosMin.Val
            PA_KeSMSw6sFamilyMdThdRwRtStFrwdBkwdPos_Val: accessed-parameter=KeSMSw6sFamilyMdThdRwRtStFrwdBkwdPos.Val
            PA_KeSMSw6sFamilyMdThdRwRtStFrwdBkwdPosMax_Val: accessed-parameter=KeSMSw6sFamilyMdThdRwRtStFrwdBkwdPosMax.Val
            PA_KeSMSw6sFamilyMdThdRwRtStFrwdBkwdPosMin_Val: accessed-parameter=KeSMSw6sFamilyMdThdRwRtStFrwdBkwdPosMin.Val
            PA_KeSMSw6sFamilyRMdThdRwRtStFrwdBkwdPos_Val: accessed-parameter=KeSMSw6sFamilyRMdThdRwRtStFrwdBkwdPos.Val
            PA_KeSMSw6sFamilyRMdThdRwRtStFrwdBkwdPosMax_Val: accessed-parameter=KeSMSw6sFamilyRMdThdRwRtStFrwdBkwdPosMax.Val
            PA_KeSMSw6sFamilyRMdThdRwRtStFrwdBkwdPosMin_Val: accessed-parameter=KeSMSw6sFamilyRMdThdRwRtStFrwdBkwdPosMin.Val
            PA_KeSMSw6sLugThdRwRtStBkReclnUpwdDnwdPos_Val: accessed-parameter=KeSMSw6sLugThdRwRtStBkReclnUpwdDnwdPos.Val
            PA_KeSMSw6sLugThdRwRtStBkReclnUpwdDnwdPosMax_Val: accessed-parameter=KeSMSw6sLugThdRwRtStBkReclnUpwdDnwdPosMax.Val
            PA_KeSMSw6sLugThdRwRtStBkReclnUpwdDnwdPosMin_Val: accessed-parameter=KeSMSw6sLugThdRwRtStBkReclnUpwdDnwdPosMin.Val
            PA_KeSMSw6sLugThdRwRtStCshnFldUpwdDnwdPos_Val: accessed-parameter=KeSMSw6sLugThdRwRtStCshnFldUpwdDnwdPos.Val
            PA_KeSMSw6sLugThdRwRtStCshnFldUpwdDnwdPosMax_Val: accessed-parameter=KeSMSw6sLugThdRwRtStCshnFldUpwdDnwdPosMax.Val
            PA_KeSMSw6sLugThdRwRtStCshnFldUpwdDnwdPosMin_Val: accessed-parameter=KeSMSw6sLugThdRwRtStCshnFldUpwdDnwdPosMin.Val
            PA_KeSMSw6sLugThdRwRtStFrwdBkwdPos_Val: accessed-parameter=KeSMSw6sLugThdRwRtStFrwdBkwdPos.Val
            PA_KeSMSw6sLugThdRwRtStFrwdBkwdPosMax_Val: accessed-parameter=KeSMSw6sLugThdRwRtStFrwdBkwdPosMax.Val
            PA_KeSMSw6sLugThdRwRtStFrwdBkwdPosMin_Val: accessed-parameter=KeSMSw6sLugThdRwRtStFrwdBkwdPosMin.Val
            PA_KeSMSw6sVIPThdRwRtStBkReclnUpwdDnwdPos_Val: accessed-parameter=KeSMSw6sVIPThdRwRtStBkReclnUpwdDnwdPos.Val
            PA_KeSMSw6sVIPThdRwRtStBkReclnUpwdDnwdPosMax_Val: accessed-parameter=KeSMSw6sVIPThdRwRtStBkReclnUpwdDnwdPosMax.Val
            PA_KeSMSw6sVIPThdRwRtStBkReclnUpwdDnwdPosMin_Val: accessed-parameter=KeSMSw6sVIPThdRwRtStBkReclnUpwdDnwdPosMin.Val
            PA_KeSMSw6sVIPThdRwRtStFrwdBkwdPos_Val: accessed-parameter=KeSMSw6sVIPThdRwRtStFrwdBkwdPos.Val
            PA_KeSMSw6sVIPThdRwRtStFrwdBkwdPosMax_Val: accessed-parameter=KeSMSw6sVIPThdRwRtStFrwdBkwdPosMax.Val
            PA_KeSMSw6sVIPThdRwRtStFrwdBkwdPosMin_Val: accessed-parameter=KeSMSw6sVIPThdRwRtStFrwdBkwdPosMin.Val
            PA_KeSMSwAcsEntryThdRwRtStBkReclnUpwdDnwdPos_Val: accessed-parameter=KeSMSwAcsEntryThdRwRtStBkReclnUpwdDnwdPos.Val
            PA_KeSMSwAcsEntryThdRwRtStBkReclnUpwdDnwdPosMax_Val: accessed-parameter=KeSMSwAcsEntryThdRwRtStBkReclnUpwdDnwdPosMax.Val
            PA_KeSMSwAcsEntryThdRwRtStBkReclnUpwdDnwdPosMin_Val: accessed-parameter=KeSMSwAcsEntryThdRwRtStBkReclnUpwdDnwdPosMin.Val
            PA_KeSMSwAcsEntryThdRwRtStCshnFldUpwdDnwdPos_Val: accessed-parameter=KeSMSwAcsEntryThdRwRtStCshnFldUpwdDnwdPos.Val
            PA_KeSMSwAcsEntryThdRwRtStCshnFldUpwdDnwdPosMax_Val: accessed-parameter=KeSMSwAcsEntryThdRwRtStCshnFldUpwdDnwdPosMax.Val
            PA_KeSMSwAcsEntryThdRwRtStCshnFldUpwdDnwdPosMin_Val: accessed-parameter=KeSMSwAcsEntryThdRwRtStCshnFldUpwdDnwdPosMin.Val
            PA_KeSMSwAcsEntryThdRwRtStFrwdBkwdPos_Val: accessed-parameter=KeSMSwAcsEntryThdRwRtStFrwdBkwdPos.Val
            PA_KeSMSwAcsEntryThdRwRtStFrwdBkwdPosMax_Val: accessed-parameter=KeSMSwAcsEntryThdRwRtStFrwdBkwdPosMax.Val
            PA_KeSMSwAcsEntryThdRwRtStFrwdBkwdPosMin_Val: accessed-parameter=KeSMSwAcsEntryThdRwRtStFrwdBkwdPosMin.Val
            PA_KeSMSwAcsMd53ThdRwRtBkReclnUpwdDnwdPos_Val: accessed-parameter=KeSMSwAcsMd53ThdRwRtBkReclnUpwdDnwdPos.Val
            PA_KeSMSwAcsMd53ThdRwRtBkReclnUpwdDnwdPosMax_Val: accessed-parameter=KeSMSwAcsMd53ThdRwRtBkReclnUpwdDnwdPosMax.Val
            PA_KeSMSwAcsMd53ThdRwRtBkReclnUpwdDnwdPosMin_Val: accessed-parameter=KeSMSwAcsMd53ThdRwRtBkReclnUpwdDnwdPosMin.Val
            PA_KeSMSwAcsMd53ThdRwRtFldUpwdDnwdPos_Val: accessed-parameter=KeSMSwAcsMd53ThdRwRtFldUpwdDnwdPos.Val
            PA_KeSMSwAcsMd53ThdRwRtFldUpwdDnwdPosMax_Val: accessed-parameter=KeSMSwAcsMd53ThdRwRtFldUpwdDnwdPosMax.Val
            PA_KeSMSwAcsMd53ThdRwRtFldUpwdDnwdPosMin_Val: accessed-parameter=KeSMSwAcsMd53ThdRwRtFldUpwdDnwdPosMin.Val
            PA_KeSMSwAcsMd56ThdRwRtStBkReclnUpwdDnwdPos_Val: accessed-parameter=KeSMSwAcsMd56ThdRwRtStBkReclnUpwdDnwdPos.Val
            PA_KeSMSwAcsMd56ThdRwRtStBkReclnUpwdDnwdPosMax_Val: accessed-parameter=KeSMSwAcsMd56ThdRwRtStBkReclnUpwdDnwdPosMax.Val
            PA_KeSMSwAcsMd56ThdRwRtStBkReclnUpwdDnwdPosMin_Val: accessed-parameter=KeSMSwAcsMd56ThdRwRtStBkReclnUpwdDnwdPosMin.Val
            PA_KeSMSwAcsMd56ThdRwRtStCshnFldUpwdDnwdPos_Val: accessed-parameter=KeSMSwAcsMd56ThdRwRtStCshnFldUpwdDnwdPos.Val
            PA_KeSMSwAcsMd56ThdRwRtStCshnFldUpwdDnwdPosMax_Val: accessed-parameter=KeSMSwAcsMd56ThdRwRtStCshnFldUpwdDnwdPosMax.Val
            PA_KeSMSwAcsMd56ThdRwRtStCshnFldUpwdDnwdPosMin_Val: accessed-parameter=KeSMSwAcsMd56ThdRwRtStCshnFldUpwdDnwdPosMin.Val
            PA_KeSMSwAcsMd56ThdRwRtStFrwdBkwdPos_Val: accessed-parameter=KeSMSwAcsMd56ThdRwRtStFrwdBkwdPos.Val
            PA_KeSMSwAcsMd56ThdRwRtStFrwdBkwdPosMax_Val: accessed-parameter=KeSMSwAcsMd56ThdRwRtStFrwdBkwdPosMax.Val
            PA_KeSMSwAcsMd56ThdRwRtStFrwdBkwdPosMin_Val: accessed-parameter=KeSMSwAcsMd56ThdRwRtStFrwdBkwdPosMin.Val
            PA_KeSMSwAcsMd57ThdRwRtStBkReclnUpwdDnwdPos_Val: accessed-parameter=KeSMSwAcsMd57ThdRwRtStBkReclnUpwdDnwdPos.Val
            PA_KeSMSwAcsMd57ThdRwRtStBkReclnUpwdDnwdPosMax_Val: accessed-parameter=KeSMSwAcsMd57ThdRwRtStBkReclnUpwdDnwdPosMax.Val
            PA_KeSMSwAcsMd57ThdRwRtStBkReclnUpwdDnwdPosMin_Val: accessed-parameter=KeSMSwAcsMd57ThdRwRtStBkReclnUpwdDnwdPosMin.Val
            PA_KeSMSwAcsMd57ThdRwRtStFrwdBkwdPos_Val: accessed-parameter=KeSMSwAcsMd57ThdRwRtStFrwdBkwdPos.Val
            PA_KeSMSwAcsMd57ThdRwRtStFrwdBkwdPosMax_Val: accessed-parameter=KeSMSwAcsMd57ThdRwRtStFrwdBkwdPosMax.Val
            PA_KeSMSwAcsMd57ThdRwRtStFrwdBkwdPosMin_Val: accessed-parameter=KeSMSwAcsMd57ThdRwRtStFrwdBkwdPosMin.Val
            PA_KeSMSwAcsMd7ThdRwRtStBkReclnUpwdDnwdPos_Val: accessed-parameter=KeSMSwAcsMd7ThdRwRtStBkReclnUpwdDnwdPos.Val
            PA_KeSMSwAcsMd7ThdRwRtStBkReclnUpwdDnwdPosMax_Val: accessed-parameter=KeSMSwAcsMd7ThdRwRtStBkReclnUpwdDnwdPosMax.Val
            PA_KeSMSwAcsMd7ThdRwRtStBkReclnUpwdDnwdPosMin_Val: accessed-parameter=KeSMSwAcsMd7ThdRwRtStBkReclnUpwdDnwdPosMin.Val
            PA_KeSMSwAcsMd7ThdRwRtStCshnFldUpwdDnwdPos_Val: accessed-parameter=KeSMSwAcsMd7ThdRwRtStCshnFldUpwdDnwdPos.Val
            PA_KeSMSwAcsMd7ThdRwRtStCshnFldUpwdDnwdPosMax_Val: accessed-parameter=KeSMSwAcsMd7ThdRwRtStCshnFldUpwdDnwdPosMax.Val
            PA_KeSMSwAcsMd7ThdRwRtStCshnFldUpwdDnwdPosMin_Val: accessed-parameter=KeSMSwAcsMd7ThdRwRtStCshnFldUpwdDnwdPosMin.Val
            PA_KeSMSwAcsMd7ThdRwRtStFrwdBkwdPos_Val: accessed-parameter=KeSMSwAcsMd7ThdRwRtStFrwdBkwdPos.Val
            PA_KeSMSwAcsMd7ThdRwRtStFrwdBkwdPosMax_Val: accessed-parameter=KeSMSwAcsMd7ThdRwRtStFrwdBkwdPosMax.Val
            PA_KeSMSwAcsMd7ThdRwRtStFrwdBkwdPosMin_Val: accessed-parameter=KeSMSwAcsMd7ThdRwRtStFrwdBkwdPosMin.Val
            PA_KeSMSwFamilyMdThdRwRtStFrwdBkwdPos_Val: accessed-parameter=KeSMSwFamilyMdThdRwRtStFrwdBkwdPos.Val
            PA_KeSMSwFamilyMdThdRwRtStFrwdBkwdPosMax_Val: accessed-parameter=KeSMSwFamilyMdThdRwRtStFrwdBkwdPosMax.Val
            PA_KeSMSwFamilyMdThdRwRtStFrwdBkwdPosMin_Val: accessed-parameter=KeSMSwFamilyMdThdRwRtStFrwdBkwdPosMin.Val
            PA_KeSMSwFamilyRMdThdRwRtStFrwdBkwdPos_Val: accessed-parameter=KeSMSwFamilyRMdThdRwRtStFrwdBkwdPos.Val
            PA_KeSMSwFamilyRMdThdRwRtStFrwdBkwdPosMax_Val: accessed-parameter=KeSMSwFamilyRMdThdRwRtStFrwdBkwdPosMax.Val
            PA_KeSMSwFamilyRMdThdRwRtStFrwdBkwdPosMin_Val: accessed-parameter=KeSMSwFamilyRMdThdRwRtStFrwdBkwdPosMin.Val
            PA_KeSMSwLugThdRwRtStBkReclnUpwdDnwdPos_Val: accessed-parameter=KeSMSwLugThdRwRtStBkReclnUpwdDnwdPos.Val
            PA_KeSMSwLugThdRwRtStBkReclnUpwdDnwdPosMax_Val: accessed-parameter=KeSMSwLugThdRwRtStBkReclnUpwdDnwdPosMax.Val
            PA_KeSMSwLugThdRwRtStBkReclnUpwdDnwdPosMin_Val: accessed-parameter=KeSMSwLugThdRwRtStBkReclnUpwdDnwdPosMin.Val
            PA_KeSMSwLugThdRwRtStCshnFldUpwdDnwdPos_Val: accessed-parameter=KeSMSwLugThdRwRtStCshnFldUpwdDnwdPos.Val
            PA_KeSMSwLugThdRwRtStCshnFldUpwdDnwdPosMax_Val: accessed-parameter=KeSMSwLugThdRwRtStCshnFldUpwdDnwdPosMax.Val
            PA_KeSMSwLugThdRwRtStCshnFldUpwdDnwdPosMin_Val: accessed-parameter=KeSMSwLugThdRwRtStCshnFldUpwdDnwdPosMin.Val
            PA_KeSMSwLugThdRwRtStFrwdBkwdPos_Val: accessed-parameter=KeSMSwLugThdRwRtStFrwdBkwdPos.Val
            PA_KeSMSwLugThdRwRtStFrwdBkwdPosMax_Val: accessed-parameter=KeSMSwLugThdRwRtStFrwdBkwdPosMax.Val
            PA_KeSMSwLugThdRwRtStFrwdBkwdPosMin_Val: accessed-parameter=KeSMSwLugThdRwRtStFrwdBkwdPosMin.Val
            PA_KeSMSwVIPThdRwRtStBkReclnUpwdDnwdPos_Val: accessed-parameter=KeSMSwVIPThdRwRtStBkReclnUpwdDnwdPos.Val
            PA_KeSMSwVIPThdRwRtStBkReclnUpwdDnwdPosMax_Val: accessed-parameter=KeSMSwVIPThdRwRtStBkReclnUpwdDnwdPosMax.Val
            PA_KeSMSwVIPThdRwRtStBkReclnUpwdDnwdPosMin_Val: accessed-parameter=KeSMSwVIPThdRwRtStBkReclnUpwdDnwdPosMin.Val
            PA_KeSMSwVIPThdRwRtStFrwdBkwdPos_Val: accessed-parameter=KeSMSwVIPThdRwRtStFrwdBkwdPos.Val
            PA_KeSMSwVIPThdRwRtStFrwdBkwdPosMax_Val: accessed-parameter=KeSMSwVIPThdRwRtStFrwdBkwdPosMax.Val
            PA_KeSMSwVIPThdRwRtStFrwdBkwdPosMin_Val: accessed-parameter=KeSMSwVIPThdRwRtStFrwdBkwdPosMin.Val
  swc implementation ThdRwRtStCalib_Implementation: behavior=ThdRwRtStCalib_InternalBehavior
    code-descriptors:
      code Default: artifact-descriptors=autosar-engineering-object={short-label=Default, category=SWSRC}
package /PATAC/MSM/ModeAdjust/CalPortInterface
  parameter interface Pos
    parameter data prototype Val: sw-calibration-access=READ-WRITE, type=UInt16
package /PATAC/MSM/ModeAdjust/DataType
  impl type TrgtPosCalibArray: category=ARRAY, sw-calibration-access=READ-ONLY, type-emitter=RTE  # 0:pos 1:max 2:min
    element Element: array-size=3, array-size-semantics=FIXED-SIZE, implementation-data-type=UInt16, invalid-value=0
package /PATAC/MSM/ModeAdjust/Interfaces
  sender receiver interface IfVeSMSuThdRwRtStCshnFldUpwdDnwdPos: invalidation-policy{data-element=Val, handle-invalid=DONT-INVALIDATE}
    data Val: type=UInt16
package /PATAC/MSM/ModeAdjust/PortInterface
  5 x client server interface:
    Md58TrgtPos
      operation Get
        12 x arg, all with type=UInt16, direction=OUT, server-argument-impl-policy=USE-ARGUMENT-TYPE:
          SecRwRtStBkReclnTrgtPos
          SecRwRtStZeroTrgtPos
          SecRwRtStLgrstUpwdDnwdTrgtPos
          SecRwRtStLgrstInwdOtwdTrgtPos
          ThdRwLtStBkReclnTrgtPos
          ThdRwLtStFwdBkwdTrgtPos
          ThdRwRtStBkReclnTrgtPos
          ThdRwRtStFwdBkwdTrgtPos
          PassStBkReclnTrgtPos
          PassStFwdBkwdTrgtPos
          SecRwRtStFwdBkwdTrgtPos
          PassStFldTrgtPos
      operation Set
    ThdRwRtStBkReclnTrgtPosSelc
      operation Cal
    ThdRwRtStCshnFldTrgtPosSelc
      operation Cal
    ThdRwRtStFwdBkwdTrgtPosSelc
      operation Cal
    VIPRExit557TrgtPos
      operation Get
        11 x arg, all with type=UInt16, direction=OUT, server-argument-impl-policy=USE-ARGUMENT-TYPE:
          SecRwRtStBkReclnTrgtPos
          SecRwRtStZeroTrgtPos
          SecRwRtStLgrstUpwdDnwdTrgtPos
          SecRwRtStLgrstInwdOtwdTrgtPos
          ThdRwLtStBkReclnTrgtPos
          ThdRwLtStFwdBkwdTrgtPos
          ThdRwRtStBkReclnTrgtPos
          ThdRwRtStFwdBkwdTrgtPos
          PassStBkReclnTrgtPos
          PassStFwdBkwdTrgtPos
          SecRwRtStFwdBkwdTrgtPos
      operation Set
  sender receiver interface StNumFlg
    4 x data, all with type=Boolean:
      Is4s
      Is6s
      Is6s7s
      Is7s
    invalidation-policys:
      data-element=Is4s, handle-invalid=DONT-INVALIDATE
      data-element=Is6s, handle-invalid=DONT-INVALIDATE
      data-element=Is6s7s, handle-invalid=DONT-INVALIDATE
      data-element=Is7s, handle-invalid=DONT-INVALIDATE
  sender receiver interface TrgtPosCalibArray: invalidation-policy{data-element=TrgtPosArray, handle-invalid=DONT-INVALIDATE}
    data TrgtPosArray: type=TrgtPosCalibArray  # 0:Pos 1:Max 2:Min
